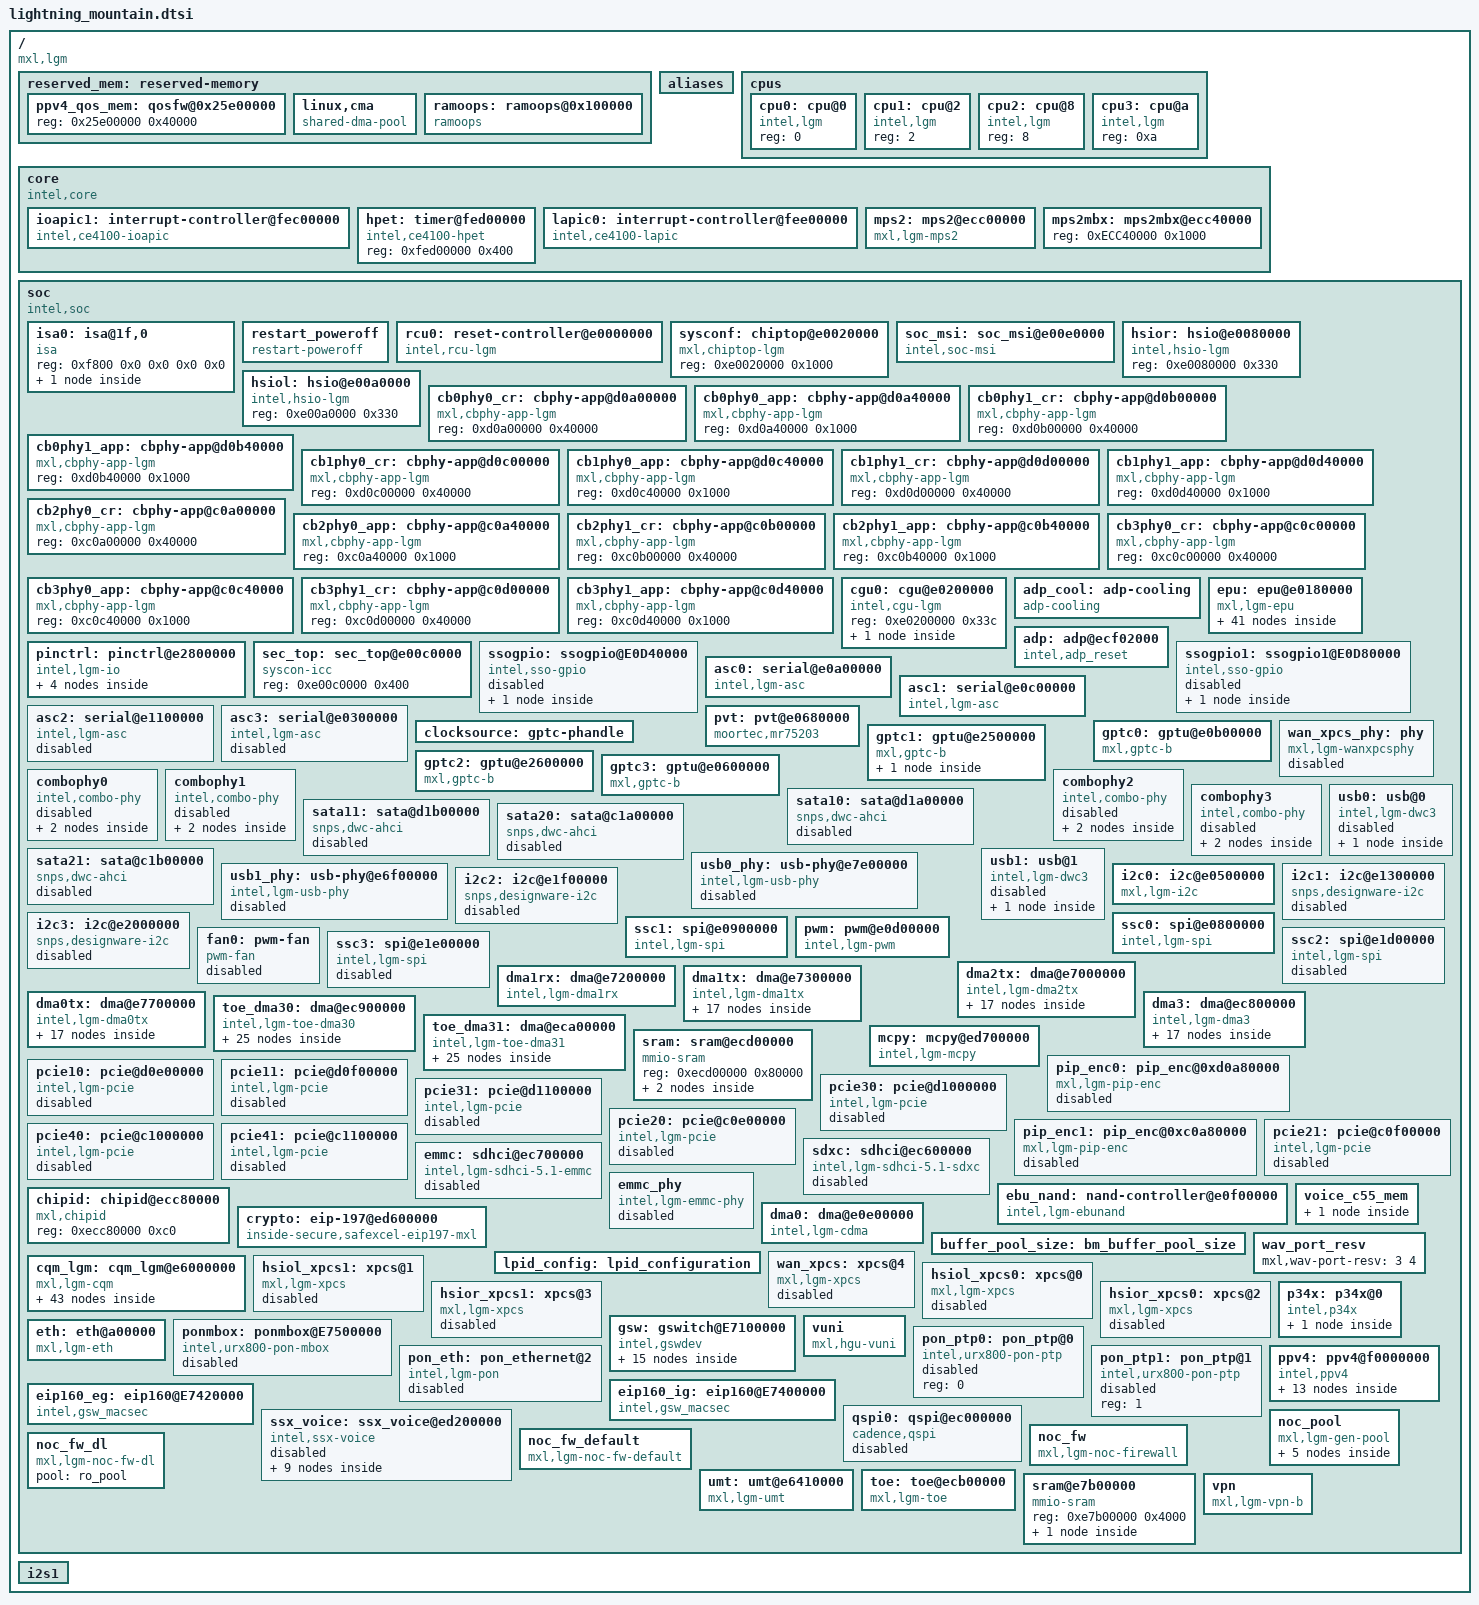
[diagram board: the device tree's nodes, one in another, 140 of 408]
// SPDX-License-Identifier: GPL-2.0
/*
 * Copyright (C) 2020-2024 MaxLinear, Inc.
 * Copyright (C) 2018-2020 Intel Corporation.
 */

#include <dt-bindings/clock/intel,lgm-clk.h>
#include <dt-bindings/phy/intel,phy-combo.h>
#include <dt-bindings/soc/mxl,firewall.h>
#include <dt-bindings/power/lgm-power.h>
#include <dt-bindings/net/mxl,lgm-cqm.h>
#include <dt-bindings/net/mxl,gswss.h>
#include <dt-bindings/net/mxl,vuni.h>

/ {
	#address-cells = <1>;
	#size-cells = <1>;
	compatible = "mxl,lgm", "intel,lgm";

	reserved_mem: reserved-memory {
		#address-cells = <1>;
		#size-cells = <1>;
		ranges;

		ppv4_qos_mem: qosfw@0x25e00000 {
			reg = <0x25e00000 0x40000>;
		};

		linux,cma {
			compatible = "shared-dma-pool";
			reusable;
			alignment = <0x200000>;
			size = <0x3f000000>;
			linux,cma-default;
		};

		ramoops: ramoops@0x100000 {
			compatible = "ramoops";
			reg = <0x100000 0x10000>;
			record-size = <0x10000>;
		};
	};

	aliases {
		serial0 = &asc0;
		serial1 = &asc1;
		serial2 = &asc2;
		serial3 = &asc3;
		dma0    = &dma2tx;
		dma1    = &dma1rx;
		dma2    = &dma1tx;
		dma3    = &dma0tx;
		dma4    = &dma3;
		dma5    = &toe_dma30;
		dma6    = &toe_dma31;
		pcie0   = &pcie10;
		pcie1   = &pcie11;
		pcie2   = &pcie30;
		pcie3   = &pcie31;
		pcie4   = &pcie20;
		pcie5   = &pcie21;
		pcie6   = &pcie40;
		pcie7   = &pcie41;
		timer0  = &gptc0;
		timer1  = &gptc1;
		timer2  = &gptc2;
		timer3  = &gptc3;
		cpu0    = &cpu0;
		cpu1    = &cpu1;
		cpu2    = &cpu2;
		cpu3    = &cpu3;
		isa0	= &isa0;
		usb0    = &usb0;
		usb1	= &usb1;
		mmc0	= &emmc;
		mmc1	= &sdxc;
		cbphy0  = &combophy0;
		cbphy1  = &combophy1;
		cbphy2  = &combophy2;
		cbphy3  = &combophy3;
		vcodec0 = &vcodec0;
		vcodec1 = &vcodec1;
		socpool = &noc_pool;
	};

	cpus {
		#address-cells = <1>;
		#size-cells = <0>;
		cpu0:cpu@0 {
			device_type = "cpu";
			compatible = "intel,lgm";
			reg = <0>;
			#cooling-cells = <2>; /* min followed by max */
		};

		cpu1:cpu@2 {
			device_type = "cpu";
			compatible = "intel,lgm";
			reg = <2>;
			#cooling-cells = <2>; /* min followed by max */
		};

		cpu2:cpu@8 {
			device_type = "cpu";
			compatible = "intel,lgm";
			reg = <8>;
			#cooling-cells = <2>; /* min followed by max */
		};

		cpu3:cpu@a {
			device_type = "cpu";
			compatible = "intel,lgm";
			reg = <0xa>;
			#cooling-cells = <2>; /* min followed by max */
		};
	};

	/* Special part from CPU core */
	core: core {
		compatible = "intel,core", "simple-bus";
		#address-cells = <1>;
		#size-cells = <1>;
		ranges;

		ioapic1: interrupt-controller@fec00000 {
			#interrupt-cells = <2>;
			#address-cells = <0>;
			compatible = "intel,ce4100-ioapic";
			interrupt-controller;
			reg = <0xfec00000 0x1000>;
			nr_entries = <256>;
		};

		hpet: timer@fed00000 {
			compatible = "intel,ce4100-hpet";
			reg = <0xfed00000 0x400>;
		};

		lapic0: interrupt-controller@fee00000 {
			compatible = "intel,ce4100-lapic";
			reg = <0xfee00000 0x1000>;
			no_pic_mode;
		};

		mps2: mps2@ecc00000 {
			status = "okay";
			compatible = "mxl,lgm-mps2", "syscon-icc", "syscon";
			reg = <0xECC00000 0x33F>;
			interrupt-parent = <&ioapic1>;
			interrupts = <168 1>;
			mxl,mbx = <&mps2mbx>;
		};

		mps2mbx: mps2mbx@ecc40000 {
			reg = <0xECC40000 0x1000>;
		};
	};

	/* Flat cross bar */
	soc: soc {
		compatible = "intel,soc", "simple-bus";
		#address-cells = <1>;
		#size-cells = <1>;
		ranges;

                isa0: isa@1f,0 {
			#address-cells = <2>;
			#size-cells = <1>;
			compatible = "isa";
			reg = <0xf800 0x0 0x0 0x0 0x0>;
			ranges = <1 0 0 0 0 0x100>;

			rtc@70 {
				compatible = "intel,ce4100-rtc", "motorola,mc146818";
				interrupts = <8 3>;
				interrupt-parent = <&ioapic1>;
				ctrl-reg = <2>;
				freq-reg = <0x26>;
				reg = <1 0x70 2>;
				status = "disabled";
			};
		};

		restart_poweroff {
			compatible = "restart-poweroff";
		};

		rcu0: reset-controller@e0000000 {
			compatible = "intel,rcu-lgm", "syscon-icc", "syscon";
			reg = <0xe0000000 0x20000>;
			#reset-cells = <2>;
			intel,global-reset = <0x10 30>;
		};

		sysconf: chiptop@e0020000 {
			compatible = "mxl,chiptop-lgm", "syscon-icc", "syscon";
			reg = <0xe0020000 0x1000>;
			#reset-cells = <1>;
		};

		soc_msi: soc_msi@e00e0000 {
			compatible = "intel,soc-msi";
			reg = <0xe00e0000 0x800>;
			interrupt-controller;
			#interrupt-cells = <1>;
			dma-coherent;
		};

		hsior:hsio@e0080000 {
			compatible = "intel,hsio-lgm", "syscon";
			reg = <0xe0080000 0x330>;
		};

		hsiol:hsio@e00a0000 {
			compatible = "intel,hsio-lgm", "syscon";
			reg = <0xe00a0000 0x330>;
		};

		cb0phy0_cr: cbphy-app@d0a00000 {
			compatible = "mxl,cbphy-app-lgm", "syscon";
			reg = <0xd0a00000 0x40000>;
		};

		cb0phy0_app: cbphy-app@d0a40000 {
			compatible = "mxl,cbphy-app-lgm", "syscon";
			reg = <0xd0a40000 0x1000>;
		};

		cb0phy1_cr: cbphy-app@d0b00000 {
			compatible = "mxl,cbphy-app-lgm", "syscon";
			reg = <0xd0b00000 0x40000>;
		};

		cb0phy1_app: cbphy-app@d0b40000 {
			compatible = "mxl,cbphy-app-lgm", "syscon";
			reg = <0xd0b40000 0x1000>;
		};

		cb1phy0_cr: cbphy-app@d0c00000 {
			compatible = "mxl,cbphy-app-lgm", "syscon";
			reg = <0xd0c00000 0x40000>;
		};

		cb1phy0_app: cbphy-app@d0c40000 {
			compatible = "mxl,cbphy-app-lgm", "syscon";
			reg = <0xd0c40000 0x1000>;
		};

		cb1phy1_cr: cbphy-app@d0d00000 {
			compatible = "mxl,cbphy-app-lgm", "syscon";
			reg = <0xd0d00000 0x40000>;
		};

		cb1phy1_app: cbphy-app@d0d40000 {
			compatible = "mxl,cbphy-app-lgm", "syscon";
			reg = <0xd0d40000 0x1000>;
		};

		cb2phy0_cr: cbphy-app@c0a00000 {
			compatible = "mxl,cbphy-app-lgm", "syscon";
			reg = <0xc0a00000 0x40000>;
		};

		cb2phy0_app: cbphy-app@c0a40000 {
			compatible = "mxl,cbphy-app-lgm", "syscon";
			reg = <0xc0a40000 0x1000>;
		};

		cb2phy1_cr: cbphy-app@c0b00000 {
			compatible = "mxl,cbphy-app-lgm", "syscon";
			reg = <0xc0b00000 0x40000>;
		};

		cb2phy1_app: cbphy-app@c0b40000 {
			compatible = "mxl,cbphy-app-lgm", "syscon";
			reg = <0xc0b40000 0x1000>;
		};

		cb3phy0_cr: cbphy-app@c0c00000 {
			compatible = "mxl,cbphy-app-lgm", "syscon";
			reg = <0xc0c00000 0x40000>;
		};

		cb3phy0_app: cbphy-app@c0c40000 {
			compatible = "mxl,cbphy-app-lgm", "syscon";
			reg = <0xc0c40000 0x1000>;
		};

		cb3phy1_cr: cbphy-app@c0d00000 {
			compatible = "mxl,cbphy-app-lgm", "syscon";
			reg = <0xc0d00000 0x40000>;
		};

		cb3phy1_app: cbphy-app@c0d40000 {
			compatible = "mxl,cbphy-app-lgm", "syscon";
			reg = <0xc0d40000 0x1000>;
		};

		cgu0: cgu@e0200000 {
			#address-cells = <1>;
			#size-cells = <1>;
			compatible = "intel,cgu-lgm", "syscon-icc", "syscon";
			reg = <0xe0200000 0x33c>;
			#clock-cells = <1>;

			afeclk: afeclk {
				#clock-cells = <0>;
				compatible = "fixed-clock";
				clock-frequency = <8000>;
				clock-output-names = "afeclk";
			};
		};

		adp_cool: adp-cooling {
			compatible = "adp-cooling";
			#cooling-cells = <2>;
		};

		epu: epu@e0180000 {
			compatible = "mxl,lgm-epu", "syscon-icc", "syscon";
			reg = <0xe0180000 0x2000    /* EPU_AON */
			       0xe0100000 0x26000>; /* EPU_GEN */
			reg-names = "epu_aon", "epu_gen";
			mxl,top-syscon = <&sysconf>;
			clocks = <&cgu0 LGM_CLK_OSC>;
			interrupt-parent = <&ioapic1>;
			interrupts = <99 1>,
				     <100 1>;
			interrupt-names = "epu_irq0", "epu_irq1";

			/*
			 * Note: LGM supports up to voltage domains including
			 * V080_CPU_MO, V080_CPU_M1, V080_ADP, V080_RoC and
			 * V080_AON
			 */

			#address-cells = <1>;
			#size-cells = <0>;

			/* ADP */
			pd_ppv4: pd_ppv4@LGM_EPU_PD_PPV4 {
				reg = <LGM_EPU_PD_PPV4>;
				#power-domain-cells = <0>;
			};

			pd_gsw: pd_gsw@LGM_EPU_PD_GSW {
				reg = <LGM_EPU_PD_GSW>;
				#power-domain-cells = <0>;
			};

			pd_cqm: pd_cqm@LGM_EPU_PD_CQM {
				reg = <LGM_EPU_PD_CQM>;
				#power-domain-cells = <0>;
			};

			pd_eip197: pd_eip197@LGM_EPU_PD_EIP197 {
				reg = <LGM_EPU_PD_EIP197>;
				#power-domain-cells = <0>;
			};

			pd_toe: pd_toe@LGM_EPU_PD_TOE {
				reg = <LGM_EPU_PD_TOE>;
				#power-domain-cells = <0>;
			};

			/* RoC */
			pd_hsio1: pd_hsio1@LGM_EPU_PD_HSIO1 {
				reg = <LGM_EPU_PD_HSIO1>;
				#power-domain-cells = <0>;
			};

			pd_hsio2: pd_hsio2@LGM_EPU_PD_HSIO2 {
				reg = <LGM_EPU_PD_HSIO2>;
				#power-domain-cells = <0>;
			};

			pd_hsio3: pd_hsio3@LGM_EPU_PD_HSIO3 {
				reg = <LGM_EPU_PD_HSIO3>;
				#power-domain-cells = <0>;
			};

			pd_hsio4: pd_hsio4@LGM_EPU_PD_HSIO4 {
				reg = <LGM_EPU_PD_HSIO4>;
				#power-domain-cells = <0>;
			};

			pd_sdxc: pd_sdxc@LGM_EPU_PD_SDXC {
				reg = <LGM_EPU_PD_SDXC>;
				#power-domain-cells = <0>;
			};

			pd_emmc: pd_emmc@LGM_EPU_PD_EMMC {
				reg = <LGM_EPU_PD_EMMC>;
				#power-domain-cells = <0>;
			};

			pd_qspi: pd_qspi@LGM_EPU_PD_QSPI {
				reg = <LGM_EPU_PD_QSPI>;
				#power-domain-cells = <0>;
			};

			pd_asc0: pd_asc0@LGM_EPU_PD_ASC0 {
				reg = <LGM_EPU_PD_ASC0>;
				#power-domain-cells = <0>;
			};

			pd_asc2: pd_asc2@LGM_EPU_PD_ASC2 {
				reg = <LGM_EPU_PD_ASC2>;
				#power-domain-cells = <0>;
			};

			pd_ssc0: pd_ssc0@LGM_EPU_PD_SSC0 {
				reg = <LGM_EPU_PD_SSC0>;
				#power-domain-cells = <0>;
			};

			pd_ssc1: pd_ssc1@LGM_EPU_PD_SSC1 {
				reg = <LGM_EPU_PD_SSC1>;
				#power-domain-cells = <0>;
			};

			pd_ssc2: pd_ssc2@LGM_EPU_PD_SSC2 {
				reg = <LGM_EPU_PD_SSC2>;
				#power-domain-cells = <0>;
			};

			pd_ssc3: pd_ssc3@LGM_EPU_PD_SSC3 {
				reg = <LGM_EPU_PD_SSC3>;
				#power-domain-cells = <0>;
			};

			pd_i2c1: pd_i2c1@LGM_EPU_PD_I2C1 {
				reg = <LGM_EPU_PD_I2C1>;
				#power-domain-cells = <0>;
			};

			pd_i2c2: pd_i2c2@LGM_EPU_PD_I2C2 {
				reg = <LGM_EPU_PD_I2C2>;
				#power-domain-cells = <0>;
			};

			pd_i2c3: pd_i2c3@LGM_EPU_PD_I2C3 {
				reg = <LGM_EPU_PD_I2C3>;
				#power-domain-cells = <0>;
			};

			pd_ebu: pd_ebu@LGM_EPU_PD_EBU {
				reg = <LGM_EPU_PD_EBU>;
				#power-domain-cells = <0>;
			};

			pd_i2s0: pd_i2s0@LGM_EPU_PD_I2S0 {
				reg = <LGM_EPU_PD_I2S0>;
				#power-domain-cells = <0>;
			};

			pd_i2s1: pd_i2s1@LGM_EPU_PD_I2S1 {
				reg = <LGM_EPU_PD_I2S1>;
				#power-domain-cells = <0>;
			};

			pd_ledc0: pd_ledc0@LGM_EPU_PD_LEDC0 {
				reg = <LGM_EPU_PD_LEDC0>;
				#power-domain-cells = <0>;
			};

			pd_ledc1: pd_ledc1@LGM_EPU_PD_LEDC1 {
				reg = <LGM_EPU_PD_LEDC1>;
				#power-domain-cells = <0>;
			};

			pd_usb1: pd_usb1@LGM_EPU_PD_USB1 {
				reg = <LGM_EPU_PD_USB1>;
				#power-domain-cells = <0>;
			};

			pd_usb2: pd_usb2@LGM_EPU_PD_USB2 {
				reg = <LGM_EPU_PD_USB2>;
				#power-domain-cells = <0>;
			};

			pd_sata0: pd_sata0@LGM_EPU_PD_SATA0 {
				reg = <LGM_EPU_PD_SATA0>;
				#power-domain-cells = <0>;
				status = "disabled";
			};

			pd_sata1: pd_sata1@LGM_EPU_PD_SATA1 {
				reg = <LGM_EPU_PD_SATA1>;
				#power-domain-cells = <0>;
				status = "disabled";
			};

			pd_sata2: pd_sata2@LGM_EPU_PD_SATA2 {
				reg = <LGM_EPU_PD_SATA2>;
				#power-domain-cells = <0>;
				status = "disabled";
			};

			pd_sata3: pd_sata3@LGM_EPU_PD_SATA3 {
				reg = <LGM_EPU_PD_SATA3>;
				#power-domain-cells = <0>;
				status = "disabled";
			};

			pd_pcie10: pd_pcie10@LGM_EPU_PD_PCIE10 {
		
				reg = <LGM_EPU_PD_PCIE10>;
				#power-domain-cells = <0>;
				status = "disabled";
			};

			pd_pcie11: pd_pcie11@LGM_EPU_PD_PCIE11 {
		
				reg = <LGM_EPU_PD_PCIE11>;
				#power-domain-cells = <0>;
				status = "disabled";
			};

			pd_pcie20: pd_pcie20@LGM_EPU_PD_PCIE20 {
				reg = <LGM_EPU_PD_PCIE20>;
				#power-domain-cells = <0>;
				status = "disabled";
			};

			pd_pcie21: pd_pcie21@LGM_EPU_PD_PCIE21 {
				reg = <LGM_EPU_PD_PCIE21>;
				#power-domain-cells = <0>;
				status = "disabled";
			};
/*
			pd_pcie30: pd_pcie30@LGM_EPU_PD_PCIE30 {
				reg = <LGM_EPU_PD_PCIE30>;
				#power-domain-cells = <0>;
			};

			pd_pcie31: pd_pcie31@LGM_EPU_PD_PCIE31 {
				reg = <LGM_EPU_PD_PCIE31>;
				#power-domain-cells = <0>;
			};
*/
			pd_pcie40: pd_pcie40@LGM_EPU_PD_PCIE40 {
				reg = <LGM_EPU_PD_PCIE40>;
				#power-domain-cells = <0>;
				status = "disabled";
			};

			pd_pcie41: pd_pcie41@LGM_EPU_PD_PCIE41 {
				reg = <LGM_EPU_PD_PCIE41>;
				#power-domain-cells = <0>;
				status = "disabled";
			};
/*
			pd_xpcs10: pd_xpcs10@LGM_EPU_PD_XPCS10 {
				reg = <LGM_EPU_PD_XPCS10>;
				#power-domain-cells = <0>;
			};
*/
			pd_xpcs11: pd_xpcs11@LGM_EPU_PD_XPCS11 {
				reg = <LGM_EPU_PD_XPCS11>;
				#power-domain-cells = <0>;
				status = "disabled";
			};
/*
			pd_xpcs20: pd_xpcs20@LGM_EPU_PD_XPCS20 {
				reg = <LGM_EPU_PD_XPCS20>;
				#power-domain-cells = <0>;
			};
*/
			pd_xpcs21: pd_xpcs21@LGM_EPU_PD_XPCS21 {
				reg = <LGM_EPU_PD_XPCS21>;
				#power-domain-cells = <0>;
				status = "disabled";
			};

			pd_voice: pd_voice@LGM_EPU_PD_VOICE {
				reg = <LGM_EPU_PD_VOICE>;
				#power-domain-cells = <0>;
			};
		};

		pinctrl: pinctrl@e2800000 {
			compatible = "intel,lgm-io";
			reg = <0xe2880000 0x100000>;
			#address-cells = <1>;
			#size-cells = <1>;
			#pinctrl-cells = <2>;
			ranges;

			pinctrl,syscon = <&sysconf>;
			gpio0: gpio@e2800000 {
				gpio-controller;
				#gpio-cells = <2>;
				reg = <0xe2800000 0x80>;
				interrupt-controller;
				#interrupt-cells = <2>;
				interrupt-parent = <&ioapic1>;
				interrupts = <135 1>;
				gpio-ranges = <&pinctrl 0 0 32>;
			};

			gpio1: gpio@e2800100 {
				gpio-controller;
				#gpio-cells = <2>;
				reg = <0xe2800100 0x80>;
				interrupt-controller;
				#interrupt-cells = <2>;
				interrupt-parent = <&ioapic1>;
				interrupts = <136 1>;
				gpio-ranges = <&pinctrl 0 32 32>;
			};

			gpio2: gpio@e2800200 {
				gpio-controller;
				#gpio-cells = <2>;
				reg = <0xe2800200 0x80>;
				interrupt-controller;
				#interrupt-cells = <2>;
				interrupt-parent = <&ioapic1>;
				interrupts = <137 1>;
				gpio-ranges = <&pinctrl 0 64 32>;
			};

			gpio3: gpio@e2800300 {
				gpio-controller;
				#gpio-cells = <2>;
				reg = <0xe2800300 0x80>;
				interrupt-controller;
				#interrupt-cells = <2>;
				interrupt-parent = <&ioapic1>;
				interrupts = <138 1>;
				gpio-ranges = <&pinctrl 0 96 8>;
			};
		};

		sec_top: sec_top@e00c0000 {
			compatible = "syscon-icc", "syscon";
			reg = <0xe00c0000 0x400>;
		};

		adp: adp@ecf02000 {
			compatible = "intel,adp_reset", "syscon-icc", "syscon";
			reg = <0xecf02000 0x1000
			       0xed500000 0x20000
			       0xe7f00000 0x8000>;
			reg-names = "eth_fw", "top_noc", "eth_noc";
			intel,sec-syscon = <&sec_top>;
			intel,top-syscon = <&sysconf>;
			intel,rcu-syscon = <&rcu0>;
			intel,epu-syscon = <&epu>;
			intel,cgu-syscon = <&cgu0>;
		};

		ssogpio: ssogpio@E0D40000 {
			status = "disabled";
			compatible = "intel,sso-gpio", "syscon", "simple-mfd";
			gpio-controller;
			#gpio-cells = <2>;
			reg = <0xE0D40000 0x2E4>;
			ngpios = <32>;
			pinctrl-names = "default";
			pinctrl-0 = <&pinctrl_ledc0>;
			clocks = <&cgu0 LGM_GCLK_LEDC0>;
			clock-names = "sso";
			resets = <&rcu0 0x30 22>;
			power-domains = <&pd_ledc0>;

			ssoled:ssoled {
				status = "disabled";
				compatible = "mxl,sso-led";
				mxl,fpid-clkrate= <8000>;
				mxl,gptc-clkrate = <200000000>;
				mxl,sso-def-updatesrc = <1>;
			};
		};

		ssogpio1: ssogpio1@E0D80000 {
			status = "disabled";
			compatible = "intel,sso-gpio", "syscon", "simple-mfd";
			gpio-controller;
			#gpio-cells = <2>;
			reg = <0xE0D80000 0x2E4>;
			ngpios = <32>;
			pinctrl-names = "default";
			pinctrl-0 = <&pinctrl_ledc1>;
			clocks = <&cgu0 LGM_GCLK_LEDC1>;
			clock-names = "sso";
			resets = <&rcu0 0x30 23>;
			power-domains = <&pd_ledc1>;

			ssoled1:ssoled1 {
				status = "disabled";
				compatible = "mxl,sso-led";
				mxl,fpid-clkrate= <8000>;
				mxl,gptc-clkrate = <200000000>;
				mxl,sso-def-updatesrc = <1>;
			};
		};

		asc0: serial@e0a00000 {
			compatible = "intel,lgm-asc";
			reg = <0xe0a00000 0x1000>;
			interrupt-parent = <&ioapic1>;
			interrupts = <128 1>;
			interrupt-names = "asc_irq";
			clocks = <&cgu0 LGM_CLK_NOC4>, <&cgu0 LGM_GCLK_ASC0>;
			clock-names = "freq", "asc";
			pinctrl-names = "default";
			pinctrl-0 = <&uart0>;
			power-domains = <&pd_asc0>;
		};

		asc1: serial@e0c00000 {
			compatible = "intel,lgm-asc";
			reg = <0xe0c00000 0x1000>;
			interrupt-parent = <&ioapic1>;
			interrupts = <111 1>;
			interrupt-names = "asc_irq";
			clocks = <&cgu0 LGM_CLK_NOC4>, <&cgu0 LGM_GCLK_ASC1>;
			clock-names = "freq", "asc";
			pinctrl-names = "default";
			pinctrl-0 = <&uart1>;
		};

		asc2: serial@e1100000 {
			status = "disabled";
			compatible = "intel,lgm-asc";
			reg = <0xe1100000 0x1000>;
			interrupt-parent = <&ioapic1>;
			interrupts = <129 1>;
			interrupt-names = "asc_irq";
			clocks = <&cgu0 LGM_CLK_NOC4>, <&cgu0 LGM_GCLK_ASC2>;
			clock-names = "freq", "asc";
			pinctrl-names = "default";
			pinctrl-0 = <&uart2>;
			power-domains = <&pd_asc2>;
		};

		asc3: serial@e0300000 {
			status = "disabled";
			compatible = "intel,lgm-asc";
			reg = <0xe0300000 0x1000>;
			interrupt-parent = <&ioapic1>;
			interrupts = <130 1>;
			interrupt-names = "asc_irq";
			clocks = <&cgu0 LGM_CLK_NOC4>, <&cgu0 LGM_GCLK_ASC3>;
			clock-names = "freq", "asc";
			pinctrl-names = "default";
			pinctrl-0 = <&uart3>;
		};

		pvt: pvt@e0680000 {
			compatible = "moortec,mr75203";
			reg = <0xe0680000 0x80
				0xe0680080 0x180
				0xe0680200 0x200
				0xe0680400 0xc00>;
			reg-names = "common", "ts", "pd", "vm";
			interrupt-parent = <&ioapic1>;
			interrupts = <26 1>;
			intel,vm-map = [01 03 04 ff ff];
			moortec,vm-active-channels = /bits/ 8 <0x01 0x01 0x01 0x00 0x00>;
			clocks = <&cgu0 LGM_CLK_OSC>;
			resets = <&rcu0 0x40 7>;
			#thermal-sensor-cells = <1>;
		};

		clocksource: gptc-phandle {
			#gptc-cells = <5>;
		};

		gptc0: gptu@e0b00000 {
			compatible = "mxl,gptc-b", "syscon", "simple-mfd";
			reg = <0xe0b00000 0x10000>;
			interrupts-extended = <&ioapic1 188 1>, <&ioapic1 189 1>,
				<&soc_msi 63>, <&soc_msi 62>;
			interrupt-names = "tc1a", "tc1b", "tc2a", "tc3a";
			mxl,clk = <&clocksource 2 0 0 32 0>, /* Heartbeat timer 1 */
				<&clocksource 3 1 0 32 0>, /* SSO timer 2 */
				<&clocksource 0 2 1 32 0>; /* Prewarn timer 3 */
			prewarn-num = <1>;
			prewarn-timer = <2 1 3>;
			mxl,wdt-rst-base = <&sysconf>;
			clocks = <&cgu0 LGM_CLK_NOC4>, <&cgu0 LGM_GCLK_GPTC0>;
			clock-names = "freq", "gptc";
		};

		gptc1: gptu@e2500000 {
			compatible = "mxl,gptc-b", "syscon", "simple-mfd";
			reg = <0xe2500000 0x10000>;
			interrupt-parent = <&soc_msi>;
			interrupts = <49>;
			interrupt-names = "tc1a";
			mxl,clk = <&clocksource 0 0 2 32 0>, /* Prewarn timer 1 */
				<&clocksource 1 1 0 32 0>,  /* Watchdog timer 2 */
				<&clocksource 1 2 1 32 0>; /* Watchdog timer 3 */
			prewarn-num = <0>;
			prewarn-timer = <0 2 0>;
			wdt-num = <1>;
			wdt-timer = <2 1>;
			mxl,wdt-rst-base = <&sysconf>;
			clocks = <&cgu0 LGM_CLK_NOC4>, <&cgu0 LGM_GCLK_GPTC1>;
			clock-names = "freq", "gptc";

			wdt0: watchdog {
				compatible = "mxl,gptc-wdt";
				timeout-sec = <30>;
				mxl,wdt-rst-base = <&sysconf>;
			};
		};

		gptc2: gptu@e2600000 {
			compatible = "mxl,gptc-b", "syscon", "simple-mfd";
			reg = <0xe2600000 0x10000>;
			interrupt-parent = <&soc_msi>;
			interrupts = <47>;
			interrupt-names = "tc1a";
			mxl,clk = <&clocksource 0 0 3 32 0>, /* Prewarn timer 1 */
				<&clocksource 1 1 2 32 0>, /* Watchdog timer 2 */
				<&clocksource 1 2 3 32 0>;  /* Watchdog timer 3 */
			prewarn-num = <0>;
			prewarn-timer = <0 3 0>;
			wdt-num = <0>;
			wdt-timer = <1 2>, <2 3>;
			mxl,wdt-rst-base = <&sysconf>;
			clocks = <&cgu0 LGM_CLK_NOC4>, <&cgu0 LGM_GCLK_GPTC2>;
			clock-names = "freq", "gptc";
		};

		gptc3: gptu@e0600000 {
			compatible = "mxl,gptc-b", "syscon", "simple-mfd";
			reg = <0xe0600000 0x10000>;
			interrupt-parent = <&ioapic1>;
			interrupts = <183 1>,
				<181 1>,
				<182 1>;
			interrupt-names = "tc1a", "tc2a", "tc3a";
			mxl,clk = <&clocksource 2 0 0 32 0>; /* Heartbeat timer 1 */
			mxl,wdt-rst-base = <&sysconf>;
			clocks = <&cgu0 LGM_CLK_OSC>, <&cgu0 LGM_GCLK_GPTC3>;
			clock-names = "freq", "gptc";
		};

		wan_xpcs_phy: phy {
			status = "disabled";
			compatible = "mxl,lgm-wanxpcsphy";
			reg = <0xe7840000 0x1000
			       0xe7800000 0x10000
			       0xe7843000 0x1000>;
			reg-names = "pon_shell", "cr", "app";
			#phy-cells = <0>;
			resets = <&rcu0 0x70 9>;
			reset-names = "pon";
			clocks = <&cgu0 LGM_CLK_SERDES>;
		};

		combophy0:combophy0 {
			status = "disabled";
			compatible = "intel,combo-phy", "simple-bus";
			#address-cells = <1>;
			#size-cells = <1>;
			ranges;

			resets = <&rcu0 0x50 17>, /* Combo */
				 <&rcu0 0x50 6>;  /* PCIe 10/11 PHY */
			reset-names = "combo", "phy";
			clocks = <&cgu0 LGM_CLK_CBPHY0>;
			intel,syscon = <&sysconf>; /* chiptop */
			intel,hsio = <&hsiol>; /* hsiol cbphy0 */
			intel,bid = <0>; /* hsio bus id */
			intel,epu-idx = <1>;
			power-domains = <&pd_hsio1>;

			cb0phy0:cb0phy@0 { /* PCIe 10/XPCS 0/SATA 0 */
				compatible = "intel,cbphy";
				#phy-cells = <1>;
				mxl,cr = <&cb0phy0_cr>;
				mxl,app = <&cb0phy0_app>;
				resets = <&rcu0 0x50 23>,
					 <&rcu0 0x50 12>;
				reset-names = "pcie", "xpcs";
			};

			cb0phy1:cb0phy@1 { /* PCIe 11/XPCS 1/SATA 1 */
				compatible = "intel,cbphy";
				#phy-cells = <1>;
				mxl,cr = <&cb0phy1_cr>;
				mxl,app = <&cb0phy1_app>;
				resets = <&rcu0 0x50 24>,
					 <&rcu0 0x50 13>;
				reset-names = "pcie", "xpcs";
			};
		};

		combophy1:combophy1 {
			status = "disabled";
			compatible = "intel,combo-phy", "simple-bus";
			#address-cells = <1>;
			#size-cells = <1>;
			ranges;

			resets = <&rcu0 0x50 8>, /* PCIe 30/31 PHY */
				 <&rcu0 0x50 18>;/* Combo */
			reset-names = "phy", "combo";
			clocks = <&cgu0 LGM_CLK_CBPHY1>;
			intel,syscon = <&sysconf>; /* chiptop */
			intel,hsio = <&hsiol>; /* hsiol cbphy1 */
			intel,bid = <1>; /* hsio bus id */
			intel,cbphy-pcie;
			power-domains = <&pd_hsio3>;

			cb1phy0:cb1phy@0 { /* PCIe 30 */
				compatible = "intel,cbphy";
				#phy-cells = <1>;
				mxl,cr = <&cb1phy0_cr>;
				mxl,app = <&cb1phy0_app>;
				resets = <&rcu0 0x50 25>;
				reset-names = "pcie"; /* pe */
			};

			cb1phy1:cb1phy@1 { /* PCIe 31 */
				compatible = "intel,cbphy";
				#phy-cells = <1>;
				mxl,cr = <&cb1phy1_cr>;
				mxl,app = <&cb1phy1_app>;
				resets = <&rcu0 0x50 26>;
				reset-names = "pcie"; /* pe */
			};
		};

		combophy2:combophy2 {
			status = "disabled";
			compatible = "intel,combo-phy", "simple-bus";
			#address-cells = <1>;
			#size-cells = <1>;
			ranges;

			resets = <&rcu0 0x60 17>, /* COMBO */
				 <&rcu0 0x60 6>;  /* PCIe 20/21 PHY */
			reset-names = "combo", "phy";
			clocks = <&cgu0 LGM_CLK_CBPHY2>;
			intel,syscon = <&sysconf>; /* chiptop */
			intel,hsio = <&hsior>; /* hsior cbphy0 */
			intel,bid = <0>; /* hsio bus id */
			intel,epu-idx = <2>;
			power-domains = <&pd_hsio2>;

			cb2phy0:cb2phy@0 { /* PCIe 20/XPCS 2/SATA 2 */
				compatible = "intel,cbphy";
				#phy-cells = <1>;
				mxl,cr = <&cb2phy0_cr>;
				mxl,app = <&cb2phy0_app>;
				resets = <&rcu0 0x60 23>,
					 <&rcu0 0x60 12>;
				reset-names = "pcie", "xpcs";
			};

			cb2phy1:cb2phy@1 { /* PCIe 21/XPCS 3/SATA 3 */
				compatible = "intel,cbphy";
				#phy-cells = <1>;
				mxl,cr = <&cb2phy1_cr>;
				mxl,app = <&cb2phy1_app>;
				resets = <&rcu0 0x60 24>,
					 <&rcu0 0x60 13>;
				reset-names = "pcie", "xpcs";
			};
		};

		combophy3:combophy3 {
			status = "disabled";
			compatible = "intel,combo-phy", "simple-bus";
			#address-cells = <1>;
			#size-cells = <1>;
			ranges;

			resets = <&rcu0 0x60 8>, /* PCIe 40/41 PHY */
				 <&rcu0 0x60 18>;/* Combo */
			reset-names = "phy", "combo";
			clocks = <&cgu0 LGM_CLK_CBPHY3>;
			intel,syscon = <&sysconf>; /* chiptop */
			intel,hsio = <&hsior>; /* hsior cbphy1 */
			intel,bid = <1>; /* hsio bus id */
			intel,cbphy-pcie;
			power-domains = <&pd_hsio4>;

			cb3phy0:cb3phy@0 { /* PCIe 40 */
				compatible = "intel,cbphy";
				#phy-cells = <1>;
				mxl,cr = <&cb3phy0_cr>;
				mxl,app = <&cb3phy0_app>;
				resets = <&rcu0 0x60 25>;
				reset-names = "pcie"; /* pe */
			};

			cb3phy1:cb3phy@1 { /* PCIe 41 */
				compatible = "intel,cbphy";
				#phy-cells = <1>;
				mxl,cr = <&cb3phy1_cr>;
				mxl,app = <&cb3phy1_app>;
				resets = <&rcu0 0x60 26>;
				reset-names = "pcie";  /* pe */
			};
		};

		sata10: sata@d1a00000 {
			status = "disabled";
			compatible = "snps,dwc-ahci";
			reg = <0xd1a00000 0x200>;
			interrupt-parent = <&soc_msi>;
			interrupts = <46>;
			clocks = <&cgu0 LGM_GCLK_SATA0>;
			resets = <&rcu0 0x50 15>;
			phys = <&cb0phy0 PHY_TYPE_SATA_SL>;
			phy-names = "sata-phy";
			ports-implemented = <0x1>;
			dma-coherent;
		};

		sata11: sata@d1b00000 {
			status = "disabled";
			compatible = "snps,dwc-ahci";
			reg = <0xd1b00000 0x200>;
			interrupt-parent = <&ioapic1>;
			interrupts = <87 1>;
			clocks = <&cgu0 LGM_GCLK_SATA1>;
			resets = <&rcu0 0x50 16>;
			phys = <&cb0phy1 PHY_TYPE_SATA_SL>;
			phy-names = "sata-phy";
			ports-implemented = <0x1>;
			dma-coherent;
		};

		sata20: sata@c1a00000 {
			status = "disabled";
			compatible = "snps,dwc-ahci";
			reg = <0xc1a00000 0x200>;
			interrupt-parent = <&soc_msi>;
			interrupts = <48>;
			clocks = <&cgu0 LGM_GCLK_SATA2>;
			resets = <&rcu0 0x60 15>;
			phys = <&cb2phy0 PHY_TYPE_SATA_SL>;
			phy-names = "sata-phy";
			ports-implemented = <0x1>;
			dma-coherent;
		};

		sata21: sata@c1b00000 {
			status = "disabled";
			compatible = "snps,dwc-ahci";
			reg = <0xc1b00000 0x200>;
			interrupt-parent = <&ioapic1>;
			interrupts = <93 1>;
			clocks = <&cgu0 LGM_GCLK_SATA3>;
			resets = <&rcu0 0x60 16>;
			phys = <&cb2phy1 PHY_TYPE_SATA_SL>;
			phy-names = "sata-phy";
			ports-implemented = <0x1>;
			dma-coherent;
		};

		usb0:usb@0 {
			status = "disabled";
			compatible = "intel,lgm-dwc3";
			#address-cells = <1>;
			#size-cells = <1>;
			ranges;
			dma-coherent;
			clocks = <&cgu0 LGM_GCLK_USB1>;
			dwc3@e7d00000 {
				compatible = "snps,dwc3";
				reg = <0xe7d00000 0x10000>;
				interrupt-parent = <&ioapic1>;
				interrupts = <47 1>;
				dr_mode = "host";
				usb-phy = <&usb0_phy>;
			};
	        };

		usb0_phy:usb-phy@e7e00000 {
			status = "disabled";
			compatible ="intel,lgm-usb-phy";
			reg = <0xe7e00000 0x10000>;
			interrupt-parent = <&ioapic1>;
			interrupts = <46 1>;
			power-domains = <&pd_usb1>;
			resets = <&rcu0 0x70 22>, <&rcu0 0x70 26>,
				 <&rcu0 0x70 24>, <&rcu0 0x70 28>;
			reset-names = "ctrl", "apb", "phy", "phy31";
			#phy-cells = <0>;
		};

		usb1:usb@1 {
			status = "disabled";
			compatible = "intel,lgm-dwc3";
			#address-cells = <1>;
			#size-cells = <1>;
			ranges;
			dma-coherent;
			clocks = <&cgu0 LGM_GCLK_USB2>;
			dwc3@e6e00000 {
				compatible = "snps,dwc3";
				reg = <0xe6e00000 0x10000>;
				interrupt-parent = <&ioapic1>;
				interrupts = <49 1>;
				dr_mode = "host";
				usb-phy = <&usb1_phy>;
			};
		};

		usb1_phy:usb-phy@e6f00000 {
			status = "disabled";
			compatible ="intel,lgm-usb-phy";
			reg = <0xe6f00000 0x10000>;
			interrupt-parent = <&ioapic1>;
			interrupts = <48 1>;
			power-domains = <&pd_usb2>;
			resets = <&rcu0 0x70 23>, <&rcu0 0x70 27>,
				<&rcu0 0x70 25>, <&rcu0 0x70 29>;
			reset-names = "ctrl", "apb", "phy", "phy31";
			#phy-cells = <0>;
		};

		i2c0: i2c@e0500000 {
			compatible = "mxl,lgm-i2c";
			#address-cells = <1>;
			#size-cells = <0>;
			reg = <0xe0500000 0x100>;
			interrupt-parent = <&ioapic1>;
			interrupts = <41 1>;
			clocks =  <&cgu0 LGM_CLK_OSC>;
			clock-frequency = <400000>;
			i2c-sda-hold-time-ns = <400>;
			resets = <&rcu0 0x40 1>;
			pinctrl-names = "default";
			pinctrl-0 = <&pinctrl_i2c0>;
		};

		i2c1: i2c@e1300000 {
			status = "disabled";
			compatible = "snps,designware-i2c";
			#address-cells = <1>;
			#size-cells = <0>;
			reg = <0xe1300000 0x100>;
			interrupt-parent = <&ioapic1>;
			interrupts = <73 1>;
			clocks =  <&cgu0 LGM_CLK_NOC4>;
			clock-names = "freq", "i2c";
			clock-frequency = <100000>;
			i2c-sda-hold-time-ns = <500>;
			resets = <&rcu0 0x30 9>;
			power-domains = <&pd_i2c1>;
			pinctrl-names = "default";
			pinctrl-0 = <&pinctrl_i2c1>;
		};

		i2c2: i2c@e1f00000 {
			status = "disabled";
			compatible = "snps,designware-i2c";
			#address-cells = <1>;
			#size-cells = <0>;
			reg = <0xe1f00000 0x100>;
			interrupt-parent = <&ioapic1>;
			interrupts = <74 1>;
			clocks =  <&cgu0 LGM_CLK_NOC4>;
			clock-names = "freq", "i2c";
			clock-frequency = <100000>;
			i2c-sda-hold-time-ns = <500>;
			resets = <&rcu0 0x30 10>;
			power-domains = <&pd_i2c2>;
			pinctrl-names = "default";
			pinctrl-0 = <&i2c2_pon>;
		};

		i2c3: i2c@e2000000 {
			status = "disabled";
			compatible = "snps,designware-i2c";
			#address-cells = <1>;
			#size-cells = <0>;
			reg = <0xe2000000 0x100>;
			interrupt-parent = <&ioapic1>;
			interrupts = <75 1>;
			clocks =  <&cgu0 LGM_CLK_NOC4>;
			clock-names = "freq", "i2c";
			clock-frequency = <100000>;
			i2c-sda-hold-time-ns = <500>;
			resets = <&rcu0 0x30 11>;
			power-domains = <&pd_i2c3>;
			pinctrl-names = "default";
			pinctrl-0 = <&i2c3_sfp>;
		};

		ssc0: spi@e0800000 {
			compatible = "intel,lgm-spi";
			reg = <0xe0800000 0x400>;
			interrupt-parent = <&ioapic1>;
			interrupts = <35 1>;
			interrupt-names = "spi_irq";
			#address-cells = <1>;
			#size-cells = <0>;
			clocks = <&cgu0 LGM_CLK_NOC4>, <&cgu0 LGM_GCLK_SSC0>;
			clock-names = "freq", "gate";
			bits-per-word = <32>;
			max-polling-time = <30>;
			base-cs = <0>;
			num-cs = <3>;
			power-domains = <&pd_ssc0>;
		};

		ssc1: spi@e0900000 {
			compatible = "intel,lgm-spi";
			reg = <0xe0900000 0x400>;
			interrupt-parent = <&ioapic1>;
			interrupts = <115 1>;
			interrupt-names = "spi_irq";
			#address-cells = <1>;
			#size-cells = <0>;
			clocks = <&cgu0 LGM_CLK_NOC4>, <&cgu0 LGM_GCLK_SSC1>;
			clock-names = "freq", "gate";
			bits-per-word = <32>;
			max-polling-time = <30>;
			base-cs = <0>;
			num-cs = <6>;
			power-domains = <&pd_ssc1>;
		};

		pwm: pwm@e0d00000 {
			compatible = "intel,lgm-pwm";
			reg = <0xe0d00000 0x30>;
			#pwm-cells = <2>;
			clocks = <&cgu0 LGM_GCLK_PWM>;
			resets = <&rcu0 0x30 21>;
		};

		fan0: pwm-fan {
			status = "disabled";
			compatible = "pwm-fan";
		};

		ssc2: spi@e1d00000 {
			compatible = "intel,lgm-spi";
			reg = <0xe1d00000 0x400>;
			interrupt-parent = <&ioapic1>;
			interrupts = <71 1>;
			interrupt-names = "spi_irq";
			#address-cells = <1>;
			#size-cells = <1>;
			clocks = <&cgu0 LGM_CLK_NOC4>, <&cgu0 LGM_GCLK_SSC2>;
			clock-names = "freq", "gate";
			bits-per-word = <32>;
			max-polling-time = <30>;
			base-cs = <0>;
			num-cs = <3>;
			status = "disabled";
			power-domains = <&pd_ssc2>;
		};

		ssc3: spi@e1e00000 {
			compatible = "intel,lgm-spi";
			reg = <0xe1e00000 0x400>;
			interrupt-parent = <&ioapic1>;
			interrupts = <72 1>;
			interrupt-names = "spi_irq";
			#address-cells = <1>;
			#size-cells = <1>;
			clocks = <&cgu0 LGM_CLK_NOC4>, <&cgu0 LGM_GCLK_SSC3>;
			clock-names = "freq", "gate";
			pinctrl-names = "default";
			bits-per-word = <32>;
			max-polling-time = <30>;
			base-cs = <0>;
			num-cs = <2>;
			status = "disabled";
			power-domains = <&pd_ssc3>;
		};

		dma2tx: dma@e7000000 {
			compatible = "intel,lgm-dma2tx";
			reg = <0xe7000000 0x1000>;
			clocks = <&cgu0 LGM_GCLK_IDMAT2>;
			resets = <&rcu0 0x70 3>;
			#dma-cells = <1>;
			intel,dma-poll-cnt = <2>;
			mxl,dma-rs-pool = <0 8>, <1 8>, <2 8>, <3 8>, <4 8>, <5 8>, <6 8>, <7 8>, <8 8>, <9 8>, <10 0>, <11 0>, <12 0>, <13 0>, <14 0>, <15 0>;
			ldma,channels {
				#size-cells = <0>;
				#address-cells = <1>;
				dma-channels@0 {
						reg = <0>;
						chan,hdr-mode = <192 0>;
				};
				dma-channels@1 {
						reg = <1>;
						chan,hdr-mode = <192 0>;
				};
				dma-channels@2 {
						reg = <2>;
						chan,hdr-mode = <192 0>;
				};
				dma-channels@3 {
						reg = <3>;
						chan,hdr-mode = <192 0>;
				};
				dma-channels@4 {
						reg = <4>;
						chan,hdr-mode = <192 0>;
				};
				dma-channels@5 {
						reg = <5>;
						chan,hdr-mode = <192 0>;
				};
				dma-channels@6 {
						reg = <6>;
						chan,hdr-mode = <192 0>;
				};
				dma-channels@7 {
						reg = <7>;
						chan,hdr-mode = <192 0>;
				};
				dma-channels@8 {
						reg = <8>;
						chan,hdr-mode = <192 0>;
				};
				dma-channels@9 {
						reg = <9>;
						chan,hdr-mode = <192 0>;
				};
				dma-channels@10 {
						reg = <10>;
						chan,hdr-mode = <192 0>;
				};
				dma-channels@11 {
						reg = <11>;
						chan,hdr-mode = <192 0>;
				};
				dma-channels@12 {
						reg = <12>;
						chan,hdr-mode = <192 0>;
				};
				dma-channels@13 {
						reg = <13>;
						chan,hdr-mode = <192 0>;
				};
				dma-channels@14 {
						reg = <14>;
						chan,hdr-mode = <192 0>;
				};
				dma-channels@15 {
						reg = <15>;
						chan,hdr-mode = <192 0>;
				};
			};
		};

		dma1rx: dma@e7200000 {
			compatible = "intel,lgm-dma1rx";
			reg = <0xe7200000 0x1000>;
			clocks = <&cgu0 LGM_GCLK_IDMAR1>;
			resets = <&rcu0 0x70 0>;
			#dma-cells = <1>;
			intel,dma-poll-cnt = <8>;
			intel,dma-dburst-wr;
		};

		dma1tx: dma@e7300000 {
			compatible = "intel,lgm-dma1tx";
			reg = <0xe7300000 0x1000>;
			clocks = <&cgu0 LGM_GCLK_IDMAT1>;
			resets = <&rcu0 0x70 2>;
			#dma-cells = <1>;
			intel,dma-poll-cnt = <2>;
			mxl,dma-rs-pool = <0 8>, <1 8>, <2 8>, <3 8>, <4 8>, <5 8>, <6 8>, <7 8>, <8 8>, <9 8>, <10 0>, <11 0>, <12 0>, <13 0>, <14 0>, <15 0>;
			ldma,channels {
				#size-cells = <0>;
				#address-cells = <1>;
				dma-channels@0 {
						reg = <0>;
						chan,hdr-mode = <192 0>;
				};
				dma-channels@1 {
						reg = <1>;
						chan,hdr-mode = <192 0>;
				};
				dma-channels@2 {
						reg = <2>;
						chan,hdr-mode = <192 0>;
				};
				dma-channels@3 {
						reg = <3>;
						chan,hdr-mode = <192 0>;
				};
				dma-channels@4 {
						reg = <4>;
						chan,hdr-mode = <192 0>;
				};
				dma-channels@5 {
						reg = <5>;
						chan,hdr-mode = <192 0>;
				};
				dma-channels@6 {
						reg = <6>;
						chan,hdr-mode = <192 0>;
				};
				dma-channels@7 {
						reg = <7>;
						chan,hdr-mode = <192 0>;
				};
				dma-channels@8 {
						reg = <8>;
						chan,hdr-mode = <192 0>;
				};
				dma-channels@9 {
						reg = <9>;
						chan,hdr-mode = <192 0>;
				};
				dma-channels@10 {
						reg = <10>;
						chan,hdr-mode = <192 0>;
				};
				dma-channels@11 {
						reg = <11>;
						chan,hdr-mode = <192 0>;
				};
				dma-channels@12 {
						reg = <12>;
						chan,hdr-mode = <192 0>;
				};
				dma-channels@13 {
						reg = <13>;
						chan,hdr-mode = <192 0>;
				};
				dma-channels@14 {
						reg = <14>;
						chan,hdr-mode = <192 0>;
				};
				dma-channels@15 {
						reg = <15>;
						chan,hdr-mode = <192 0>;
				};
			};
		};

		dma0tx: dma@e7700000 {
			compatible = "intel,lgm-dma0tx";
			reg = <0xe7700000 0x1000>;
			clocks = <&cgu0 LGM_GCLK_IDMAT0>;
			resets = <&rcu0 0x70 1>;
			#dma-cells = <1>;
			intel,dma-poll-cnt = <2>;
			intel,dma-byte-en;
			mxl,dma-rs-pool = <0 8>, <1 8>, <2 8>, <3 8>, <4 8>, <5 8>, <6 8>, <7 8>, <8 8>, <9 8>, <10 0>, <11 0>, <12 0>, <13 0>, <14 0>, <15 0>;
			ldma,channels {
				#size-cells = <0>;
				#address-cells = <1>;
				dma-channels@0 {
						reg = <0>;
						chan,hdr-mode = <192 0>;
				};
				dma-channels@1 {
						reg = <1>;
						chan,hdr-mode = <192 0>;
				};
				dma-channels@2 {
						reg = <2>;
						chan,hdr-mode = <192 0>;
				};
				dma-channels@3 {
						reg = <3>;
						chan,hdr-mode = <192 0>;
				};
				dma-channels@4 {
						reg = <4>;
						chan,hdr-mode = <192 0>;
				};
				dma-channels@5 {
						reg = <5>;
						chan,hdr-mode = <192 0>;
				};
				dma-channels@6 {
						reg = <6>;
						chan,hdr-mode = <192 0>;
				};
				dma-channels@7 {
						reg = <7>;
						chan,hdr-mode = <192 0>;
				};
				dma-channels@8 {
						reg = <8>;
						chan,hdr-mode = <192 0>;
				};
				dma-channels@9 {
						reg = <9>;
						chan,hdr-mode = <192 0>;
				};
				dma-channels@10 {
						reg = <10>;
						chan,hdr-mode = <192 0>;
				};
				dma-channels@11 {
						reg = <11>;
						chan,hdr-mode = <192 0>;
				};
				dma-channels@12 {
						reg = <12>;
						chan,hdr-mode = <192 0>;
				};
				dma-channels@13 {
						reg = <13>;
						chan,hdr-mode = <192 1>;
				};
				dma-channels@14 {
						reg = <14>;
						chan,hdr-mode = <192 0>;
				};
				dma-channels@15 {
						reg = <15>;
						chan,hdr-mode = <192 0>;
				};
			};
		};

		dma3: dma@ec800000 {
			compatible = "intel,lgm-dma3";
			reg = <0xec800000 0x1000>;
			clocks = <&cgu0 LGM_GCLK_DMA3>;
			resets = <&rcu0 0x10 9>;
			#dma-cells = <1>;
			dma-coherent;
			intel,dma-poll-cnt = <4>;
			intel,dma-byte-en;
			intel,dma-dburst-wr;
			ldma,channels {
				#size-cells = <0>;
				#address-cells = <1>;
				dma-channels@0 {
					reg = <0>;
					chan,hw-desc = <0x600 2>;
				};
				dma-channels@1 {
					reg = <1>;
					chan,hw-desc = <0x620 2>;
				};
				dma-channels@2 {
					reg = <2>;
					chan,hw-desc = <0x700 2>;
				};
				dma-channels@3 {
					reg = <3>;
					chan,hw-desc = <0x720 2>;
				};
				dma-channels@4 {
					reg = <4>;
					chan,hw-desc = <0x800 2>;
				};
				dma-channels@5 {
					reg = <5>;
					chan,hw-desc = <0x820 2>;
				};
				dma-channels@6 {
					reg = <6>;
					chan,hw-desc = <0x900 2>;
				};
				dma-channels@7 {
					reg = <7>;
					chan,hw-desc = <0x920 2>;
				};
				dma-channels@8 {
					reg = <8>;
					chan,hw-desc = <0xa00 2>;
				};
				dma-channels@9 {
					reg = <9>;
					chan,hw-desc = <0xa20 2>;
				};
				dma-channels@10 {
					reg = <10>;
					chan,hw-desc = <0xb00 2>;
				};
				dma-channels@11 {
					reg = <11>;
					chan,hw-desc = <0xb20 2>;
				};
				dma-channels@12 {
					reg = <12>;
					chan,hw-desc = <0xc00 2>;
				};
				dma-channels@13 {
					reg = <13>;
					chan,hw-desc = <0xc20 2>;
				};
				dma-channels@14 {
					reg = <14>;
					chan,hw-desc = <0xd00 2>;
				};
				dma-channels@15 {
					reg = <15>;
					chan,hw-desc = <0xd20 2>;
				};

			};
		};

		toe_dma30: dma@ec900000 {
			compatible = "intel,lgm-toe-dma30";
			reg = <0xec900000 0x1000>;
			#dma-cells = <3>;
			intel,dma-poll-cnt = <4>;
			intel,dma-byte-en;
			intel,dma-dburst-wr;
			ldma,channels {
				#size-cells = <0>;
				#address-cells = <1>;
				dma-channels@4 {
					reg = <4>;
					chan,hw-desc = <0xecb40600 2>;
				};
				dma-channels@5 {
					reg = <5>;
					chan,hw-desc = <0xecb40620 2>;
				};
				dma-channels@8 {
					reg = <8>;
					chan,hw-desc = <0xecb41000 1>;
					chan,desc-rx-nonpost;
				};
				dma-channels@9 {
					reg = <9>;
					chan,hw-desc = <0xecb41100 2>;
				};
				dma-channels@10 {
					reg = <10>;
					chan,hw-desc = <0xecb41200 1>;
					chan,desc-rx-nonpost;
				};
				dma-channels@11 {
					reg = <11>;
					chan,hw-desc = <0xecb41300 2>;
				};
				dma-channels@6 {
					reg = <6>;
					chan,hw-desc = <0xecb40800 2>;
				};
				dma-channels@7 {
					reg = <7>;
					chan,hw-desc = <0xecb40820 2>;
				};
				dma-channels@18 {
					reg = <18>;
					chan,hw-desc = <0xecb41400 1>;
					chan,desc-rx-nonpost;
				};
				dma-channels@19 {
					reg = <19>;
					chan,hw-desc = <0xecb41500 2>;
				};
				dma-channels@20 {
					reg = <20>;
					chan,hw-desc = <0xecb41600 1>;
					chan,desc-rx-nonpost;
				};
				dma-channels@21 {
					reg = <21>;
					chan,hw-desc = <0xecb41700 2>;
				};
				dma-channels@14 {
					reg = <14>;
					chan,hw-desc = <0xecb40a00 2>;
				};
				dma-channels@15 {
					reg = <15>;
					chan,hw-desc = <0xecb40a20 2>;
				};
				dma-channels@28 {
					reg = <28>;
					chan,hw-desc = <0xecb41800 1>;
					chan,desc-rx-nonpost;
				};
				dma-channels@29 {
					reg = <29>;
					chan,hw-desc = <0xecb41900 2>;
				};
				dma-channels@30 {
					reg = <30>;
					chan,hw-desc = <0xecb41a00 1>;
					chan,desc-rx-nonpost;
				};
				dma-channels@31 {
					reg = <31>;
					chan,hw-desc = <0xecb41b00 2>;
				};
				dma-channels@16 {
					reg = <16>;
					chan,hw-desc = <0xecb40c00 2>;
				};
				dma-channels@17 {
					reg = <17>;
					chan,hw-desc = <0xecb40c20 2>;
				};
				dma-channels@22 {
					reg = <22>;
					chan,hw-desc = <0xecb41c00 1>;
					chan,desc-rx-nonpost;
				};
				dma-channels@23 {
					reg = <23>;
					chan,hw-desc = <0xecb41d00 2>;
				};
				dma-channels@24 {
					reg = <24>;
					chan,hw-desc = <0xecb41e00 1>;
					chan,desc-rx-nonpost;
				};
				dma-channels@25 {
					reg = <25>;
					chan,hw-desc = <0xecb41f00 2>;
				};
			};
		};

		toe_dma31: dma@eca00000 {
			compatible = "intel,lgm-toe-dma31";
			reg = <0xeca00000 0x1000>;
			#dma-cells = <3>;
			intel,dma-poll-cnt = <4>;
			intel,dma-byte-en;
			intel,dma-dburst-wr;
			ldma,channels {
				#size-cells = <0>;
				#address-cells = <1>;
				dma-channels@4 {
					reg = <4>;
					chan,hw-desc = <0xecb40700 2>;
				};
				dma-channels@5 {
					reg = <5>;
					chan,hw-desc = <0xecb40720 2>;
				};
				dma-channels@8 {
					reg = <8>;
					chan,hw-desc = <0xecb42000 1>;
					chan,desc-rx-nonpost;
				};
				dma-channels@9 {
					reg = <9>;
					chan,hw-desc = <0xecb42100 2>;
				};
				dma-channels@10 {
					reg = <10>;
					chan,hw-desc = <0xecb42200 1>;
					chan,desc-rx-nonpost;
				};
				dma-channels@11 {
					reg = <11>;
					chan,hw-desc = <0xecb42300 2>;
				};
				dma-channels@6 {
					reg = <6>;
					chan,hw-desc = <0xecb40900 2>;
				};
				dma-channels@7 {
					reg = <7>;
					chan,hw-desc = <0xecb40920 2>;
				};
				dma-channels@18 {
					reg = <18>;
					chan,hw-desc = <0xecb42400 1>;
					chan,desc-rx-nonpost;
				};
				dma-channels@19 {
					reg = <19>;
					chan,hw-desc = <0xecb42500 2>;
				};
				dma-channels@20 {
					reg = <20>;
					chan,hw-desc = <0xecb42600 1>;
					chan,desc-rx-nonpost;
				};
				dma-channels@21 {
					reg = <21>;
					chan,hw-desc = <0xecb42700 2>;
				};
				dma-channels@14 {
					reg = <14>;
					chan,hw-desc = <0xecb40b00 2>;
				};
				dma-channels@15 {
					reg = <15>;
					chan,hw-desc = <0xecb40b20 2>;
				};
				dma-channels@28 {
					reg = <28>;
					chan,hw-desc = <0xecb42800 1>;
					chan,desc-rx-nonpost;
				};
				dma-channels@29 {
					reg = <29>;
					chan,hw-desc = <0xecb42900 2>;
				};
				dma-channels@30 {
					reg = <30>;
					chan,hw-desc = <0xecb42a00 1>;
					chan,desc-rx-nonpost;
				};
				dma-channels@31 {
					reg = <31>;
					chan,hw-desc = <0xecb42b00 2>;
				};
				dma-channels@16 {
					reg = <16>;
					chan,hw-desc = <0xecb40d00 2>;
				};
				dma-channels@17 {
					reg = <17>;
					chan,hw-desc = <0xecb40d20 2>;
				};
				dma-channels@22 {
					reg = <22>;
					chan,hw-desc = <0xecb42c00 1>;
					chan,desc-rx-nonpost;
				};
				dma-channels@23 {
					reg = <23>;
					chan,hw-desc = <0xecb42d00 2>;
				};
				dma-channels@24 {
					reg = <24>;
					chan,hw-desc = <0xecb42e00 1>;
					chan,desc-rx-nonpost;
				};
				dma-channels@25 {
					reg = <25>;
					chan,hw-desc = <0xecb42f00 2>;
				};
			};
		};

		mcpy: mcpy@ed700000 {
			compatible = "intel,lgm-mcpy";
			reg = <0xed700000 0x10000>;
			clocks = <&cgu0 LGM_CLK_NGI>;
			clock-names = "freq";
			interrupt-parent = <&soc_msi>;
			interrupts = <36>, <37>, <38>, <39>,
				     <40>, <41>, <42>, <43>;
			dmas = <&dma3 0>, <&dma3 1>, <&dma3 2>, <&dma3 3>,
			       <&dma3 4>, <&dma3 5>, <&dma3 6>, <&dma3 7>,
			       <&dma3 8>, <&dma3 9>, <&dma3 10>, <&dma3 11>,
			       <&dma3 12>, <&dma3 13>, <&dma3 14>, <&dma3 15>;
			dma-names = "p0rx", "p0tx", "p1rx", "p1tx",
				    "p2rx", "p2tx", "p3rx", "p3tx",
				    "p4rx", "p4tx", "p5rx", "p5tx",
				    "p6rx", "p6tx", "p7rx", "p7tx";
			intel,mcpy-portnum = <8>;
			intel,mcpy-maxchksz = <3>;
			power-domains = <&pd_toe>;
		};

		sram: sram@ecd00000 {
			compatible = "mmio-sram";
			reg = <0xecd00000 0x80000>;
			#address-cells = <1>;
			#size-cells = <1>;
			ranges = <0 0xecd00000 0x80000>;

	        	cqm_sram: cqm_sram {
				reg = <0x0 0xe900>;
				pool;
			};

			toe_sram: toe_sram {
				reg = <0xe900 0x71700>;
				pool;
			};
		};

		/* pip-enc on pcie10 */
		pip_enc0: pip_enc@0xd0a80000 {
			compatible = "mxl,lgm-pip-enc";
			reg = <0xd0a80000 0x80000>;
			reg-names = "pip-enc-memory";
			interrupt-parent = <&ioapic1>;
			interrupts = <96 1>, <97 1>, <98 1>;
			interrupt-names = "crypto-ip", "rd-rsp-key-exp", "wr-key-exp";
			status = "disabled";
		};

		pcie10:pcie@d0e00000 {
			status = "disabled";
			compatible = "intel,lgm-pcie";
			device_type = "pci";
			#address-cells = <3>;
			#size-cells = <2>;
			reg = <
				0xd0e00000 0x1000 /* RC controller DBI */
				0xd0ec0000 0x1000 /* RC controller ATU */
				0xd2000000 0x20000 /* Cfg */
				0xd0a41000 0x1000 /* App logic */
			>;
			reg-names = "dbi", "atu", "config", "app";
			linux,pci-domain = <0>;
			max-link-speed = <4>;
			bus-range = <0x00 0x08>;
			interrupt-parent = <&ioapic1>;
			interrupts = <67 1>;
			interrupt-names = "ir";
			#interrupt-cells = <1>;
			interrupt-map-mask = <0 0 0 0x7>;
			interrupt-map = <0 0 0 1 &ioapic1 27 1>,
					<0 0 0 2 &ioapic1 28 1>,
					<0 0 0 3 &ioapic1 29 1>,
					<0 0 0 4 &ioapic1 30 1>;
			ranges = <0x02000000 0 0xd4000000 0xd4000000 0 0x04000000    /* Non-pretechable memory 32bit */
				 >;
			resets = <&rcu0 0x50 0>;
			reset-names =  "core";
			intel,pcie-syscon = <&sysconf>;
			intel,has_iatu;
			clocks = <&cgu0 LGM_GCLK_PCIE10>;
			clock-names ="ctl";
			phys = <&cb0phy0 PHY_TYPE_PCIE_SL>;
			phy-names = "pcie";
		};

		pcie11:pcie@d0f00000 {
			status = "disabled";
			compatible = "intel,lgm-pcie";
			device_type = "pci";
			#address-cells = <3>;
			#size-cells = <2>;
			reg = <
				0xd0f00000 0x1000 /* RC controller DBI */
				0xd0fc0000 0x1000 /* RC controller ATU */
				0xd2800000 0x20000 /* Cfg */
				0xd0b41000 0x1000 /* App logic */
			>;
			reg-names = "dbi", "atu", "config", "app";
			linux,pci-domain = <1>;
			max-link-speed = <4>;
			bus-range = <0x00 0x08>;
			interrupt-parent = <&ioapic1>;
			interrupts = <143 1>;
			interrupt-names = "ir";
			#interrupt-cells = <1>;
			interrupt-map-mask = <0 0 0 0x7>;
			interrupt-map = <0 0 0 1 &ioapic1 76 1>,
					<0 0 0 2 &ioapic1 77 1>,
					<0 0 0 3 &ioapic1 78 1>,
					<0 0 0 4 &ioapic1 79 1>;
			ranges = <0x02000000 0 0xd8000000 0xd8000000 0 0x04000000    /* Non-pretechable memory 32bit */
				 >;
			resets = <&rcu0 0x50 1>;
			reset-names =  "core";
			intel,pcie-syscon = <&sysconf>;
			intel,has_iatu;
			clocks = <&cgu0 LGM_GCLK_PCIE11>;
			clock-names ="ctl";
			phys = <&cb0phy1 PHY_TYPE_PCIE_SL>;
			phy-names = "pcie";
		};

		pcie30:pcie@d1000000 {
			status = "disabled";
			compatible = "intel,lgm-pcie";
			device_type = "pci";
			#address-cells = <3>;
			#size-cells = <2>;
			reg = <
				0xd1000000 0x1000 /* RC controller DBI */
				0xd10c0000 0x1000 /* RC controller ATU */
				0xd3000000 0x20000 /* Cfg */
				0xd0c41000 0x1000 /* App logic */
			>;
			reg-names = "dbi", "atu", "config", "app";
			linux,pci-domain = <2>;
			max-link-speed = <3>;
			bus-range = <0x00 0x08>;
			interrupt-parent = <&ioapic1>;
			interrupts = <146 1>;
			interrupt-names = "ir";
			#interrupt-cells = <1>;
			interrupt-map-mask = <0 0 0 0x7>;
			interrupt-map = <0 0 0 1 &ioapic1 216 1>,
					<0 0 0 2 &ioapic1 217 1>,
					<0 0 0 3 &ioapic1 218 1>,
					<0 0 0 4 &ioapic1 219 1>;
			ranges = <0x02000000 0 0xdc000000 0xdc000000 0 0x02000000    /* Non-pretechable memory 32bit */
				 >;
			resets = <&rcu0 0x50 2>;
			reset-names =  "core";
			intel,pcie-syscon = <&sysconf>;
			intel,has_iatu;
			clocks = <&cgu0 LGM_GCLK_PCIE30>;
			clock-names ="ctl";
			phys = <&cb1phy0 PHY_TYPE_PCIE_SL>;
			phy-names = "pcie";
		};

		pcie31:pcie@d1100000 {
			status = "disabled";
			compatible = "intel,lgm-pcie";
			device_type = "pci";
			#address-cells = <3>;
			#size-cells = <2>;
			reg = <
				0xd1100000 0x1000 /* RC controller DBI */
				0xd11c0000 0x1000 /* RC controller ATU */
				0xd3800000 0x20000 /* Cfg */
				0xd0d41000 0x1000 /* App logic */
			>;
			reg-names = "dbi", "atu", "config", "app";
			linux,pci-domain = <3>;
			max-link-speed = <3>;
			bus-range = <0x00 0x08>;
			interrupt-parent = <&ioapic1>;
			interrupts = <147 1>;
			interrupt-names = "ir";
			#interrupt-cells = <1>;
			interrupt-map-mask = <0 0 0 0x7>;
			interrupt-map = <0 0 0 1 &ioapic1 220 1>,
					<0 0 0 2 &ioapic1 221 1>,
					<0 0 0 3 &ioapic1 222 1>,
					<0 0 0 4 &ioapic1 223 1>;
			ranges = <0x02000000 0 0xde000000 0xde000000 0 0x02000000    /* Non-pretechable memory 32bit */
				 >;
			resets = <&rcu0 0x50 3>;
			reset-names =  "core";
			intel,pcie-syscon = <&sysconf>;
			intel,has_iatu;
			clocks = <&cgu0 LGM_GCLK_PCIE31>;
			clock-names ="ctl";
			phys = <&cb1phy1 PHY_TYPE_PCIE_SL>;
			phy-names = "pcie";
		};

		/* pip-enc on pcie20 */
		pip_enc1: pip_enc@0xc0a80000 {
			compatible = "mxl,lgm-pip-enc";
			reg = <0xc0a80000 0x80000>;
			reg-names = "pip-enc-memory";
			interrupt-parent = <&ioapic1>;
			interrupts = <178 1>, <179 1>, <180 1>;
			interrupt-names = "crypto-ip", "rd-rsp-key-exp", "wr-key-exp";
			status = "disabled";
		};

		pcie20:pcie@c0e00000 {
			status = "disabled";
			compatible = "intel,lgm-pcie";
			device_type = "pci";
			#address-cells = <3>;
			#size-cells = <2>;
			reg = <
				0xc0e00000 0x1000 /* RC controller DBI */
				0xc0ec0000 0x1000 /* RC controller ATU */
				0xc2000000 0x20000 /* Cfg */
				0xc0a41000 0x1000 /* App logic */
			>;
			reg-names = "dbi", "atu", "config", "app";
			linux,pci-domain = <4>;
			max-link-speed = <4>;
			bus-range = <0x00 0x08>;
			interrupt-parent = <&ioapic1>;
			interrupts = <144 1>;
			interrupt-names = "ir";
			#interrupt-cells = <1>;
			interrupt-map-mask = <0 0 0 0x7>;
			interrupt-map = <0 0 0 1 &ioapic1 116 1>,
					<0 0 0 2 &ioapic1 117 1>,
					<0 0 0 3 &ioapic1 118 1>,
					<0 0 0 4 &ioapic1 119 1>;
			ranges = <0x02000000 0 0xc4000000 0xc4000000 0 0x04000000    /* Non-pretechable memory 32bit */
				 >;
			resets = <&rcu0 0x60 0>;
			reset-names =  "core";
			intel,pcie-syscon = <&sysconf>;
			intel,has_bus_iatu;
			clocks = <&cgu0 LGM_GCLK_PCIE20>;
			clock-names ="ctl";
			phys = <&cb2phy0 PHY_TYPE_PCIE_SL>;
			phy-names = "pcie";
		};

		pcie21:pcie@c0f00000 {
			status = "disabled";
			compatible = "intel,lgm-pcie";
			device_type = "pci";
			#address-cells = <3>;
			#size-cells = <2>;
			reg = <
				0xc0f00000 0x1000 /* RC controller DBI */
				0xc0fc0000 0x1000 /* RC controller ATU */
				0xc2800000 0x20000 /* Cfg */
				0xc0b41000 0x1000 /* App logic */
			>;
			reg-names = "dbi", "atu", "config", "app";
			linux,pci-domain = <5>;
			max-link-speed = <4>;
			bus-range = <0x00 0x08>;
			interrupt-parent = <&ioapic1>;
			interrupts = <145 1>;
			interrupt-names = "ir";
			#interrupt-cells = <1>;
			interrupt-map-mask = <0 0 0 0x7>;
			interrupt-map = <0 0 0 1 &ioapic1 120 1>,
					<0 0 0 2 &ioapic1 121 1>,
					<0 0 0 3 &ioapic1 122 1>,
					<0 0 0 4 &ioapic1 123 1>;
			ranges = <0x02000000 0 0xc8000000 0xc8000000 0 0x04000000    /* Non-pretechable memory 32bit */
				 >;
			resets = <&rcu0 0x60 1>;
			reset-names =  "core";
			intel,pcie-syscon = <&sysconf>;
			intel,has_bus_iatu;
			clocks = <&cgu0 LGM_GCLK_PCIE21>;
			clock-names ="ctl";
			phys = <&cb2phy1 PHY_TYPE_PCIE_SL>;
			phy-names = "pcie";
		};

		pcie40:pcie@c1000000 {
			status = "disabled";
			compatible = "intel,lgm-pcie";
			device_type = "pci";
			#address-cells = <3>;
			#size-cells = <2>;
			reg = <
				0xc1000000 0x1000 /* RC controller DBI */
				0xc10c0000 0x1000 /* RC controller ATU */
				0xc3000000 0x20000 /* Cfg */
				0xc0c41000 0x1000 /* App logic */
			>;
			reg-names = "dbi", "atu", "config", "app";
			linux,pci-domain = <6>;
			max-link-speed = <3>;
			bus-range = <0x00 0x08>;
			interrupt-parent = <&ioapic1>;
			interrupts = <148 1>;
			interrupt-names = "ir";
			#interrupt-cells = <1>;
			interrupt-map-mask = <0 0 0 0x7>;
			interrupt-map = <0 0 0 1 &ioapic1 224 1>,
					<0 0 0 2 &ioapic1 225 1>,
					<0 0 0 3 &ioapic1 226 1>,
					<0 0 0 4 &ioapic1 227 1>;
			ranges = <0x02000000 0 0xcc000000 0xcc000000 0 0x02000000    /* Non-pretechable memory 32bit */
				 >;
			resets = <&rcu0 0x60 2>;
			reset-names =  "core";
			intel,pcie-syscon = <&sysconf>;
			intel,has_bus_iatu;
			clocks = <&cgu0 LGM_GCLK_PCIE40>;
			clock-names ="ctl";
			phys = <&cb3phy0 PHY_TYPE_PCIE_SL>;
			phy-names = "pcie";
		};

		pcie41:pcie@c1100000 {
			status = "disabled";
			compatible = "intel,lgm-pcie";
			device_type = "pci";
			#address-cells = <3>;
			#size-cells = <2>;
			reg = <
				0xc1100000 0x1000 /* RC controller DBI */
				0xc11c0000 0x1000 /* RC controller DBI */
				0xc3800000 0x20000 /* Cfg */
				0xc0d41000 0x1000 /* App logic */
			>;
			reg-names = "dbi", "atu", "config", "app";
			linux,pci-domain = <7>;
			max-link-speed = <3>;
			bus-range = <0x00 0x08>;
			interrupt-parent = <&ioapic1>;
			interrupts = <149 1>;
			interrupt-names = "ir";
			#interrupt-cells = <1>;
			interrupt-map-mask = <0 0 0 0x7>;
			interrupt-map = <0 0 0 1 &ioapic1 228 1>,
					<0 0 0 2 &ioapic1 229 1>,
					<0 0 0 3 &ioapic1 230 1>,
					<0 0 0 4 &ioapic1 231 1>;
			ranges = <0x02000000 0 0xce000000 0xce000000 0 0x02000000    /* Non-pretechable memory 32bit */
				 >;
			resets = <&rcu0 0x60 3>;
			reset-names =  "core";
			intel,pcie-syscon = <&sysconf>;
			intel,has_bus_iatu;
			clocks = <&cgu0 LGM_GCLK_PCIE41>;
			clock-names ="ctl";
			phys = <&cb3phy1 PHY_TYPE_PCIE_SL>;
			phy-names = "pcie";
		};

		sdxc: sdhci@ec600000 {
			status = "disabled";
			compatible = "intel,lgm-sdhci-5.1-sdxc";
			reg = <0xec600000 0x300>;
			interrupt-parent = <&ioapic1>;
			interrupts = <43 1>;
			clocks = <&cgu0 LGM_CLK_SDXC>, <&cgu0 LGM_GCLK_SDXC>;
			clock-names = "clk_xin", "clk_ahb";
			clock-output-names = "sdxc_cardclock", "sdxc_sampleclock";
			#clock-cells = <1>;
			arasan,soc-ctl-syscon = <&sysconf>;
			dma-coherent;
			clk-phase-sd-hs = <0>, <180>;
			clk-phase-uhs-sdr50 = <0>, <180>;
			clk-phase-uhs-sdr104 = <0>, <180>;
			power-domains = <&pd_sdxc>;
		};

		emmc: sdhci@ec700000 {
			status = "disabled";
			compatible = "intel,lgm-sdhci-5.1-emmc",
				     "arasan,sdhci-5.1";
			reg = <0xec700000 0x300>;
			interrupt-parent = <&ioapic1>;
			interrupts = <44 1>;
			clocks = <&cgu0 LGM_CLK_EMMC>, <&cgu0 LGM_GCLK_EMMC>;
			clock-names = "clk_xin", "clk_ahb";
			clock-frequency = <200000000>;
			clock-output-names = "emmc_cardclock", "emmc_sampleclock";
			#clock-cells = <1>;
			phys = <&emmc_phy>;
			phy-names = "phy_arasan";
			arasan,soc-ctl-syscon = <&sysconf>;
			dma-coherent;
			clk-phase-mmc-hs200 = <0>, <180>;
			clk-phase-mmc-hs400 = <0>, <90>;
			power-domains = <&pd_emmc>;
		};

		emmc_phy: emmc_phy {
			status = "disabled";
			compatible = "intel,lgm-emmc-phy";
			intel,syscon = <&sysconf>;
			clocks = <&emmc 0>;
			clock-names = "emmcclk";
			#phy-cells = <0>;
		};

		ebu_nand: nand-controller@e0f00000 {
			compatible = "intel,lgm-ebunand";
			reg = <0xe0f00000 0x100>,
			      <0xe1000000 0x300>,
			      <0xe1400000 0x80000>,
			      <0xe1c00000 0x10000>,
			      <0x17400000 0x4>,
			      <0x17c00000 0x4>;
			reg-names = "ebunand", "hsnand", "nand_cs1", "nand_cs0",
				    "addr_sel0", "addr_sel1";
			clocks = <&cgu0 LGM_GCLK_EBU>;
			dmas = <&dma0 8 4 8>, <&dma0 9 4 8>;
			dma-names = "rx", "tx";
			power-domains = <&pd_ebu>;
			dma-coherent;
			#address-cells = <1>;
			#size-cells = <0>;
		};

		chipid: chipid@ecc80000{
			compatible = "mxl,chipid";
			reg = <0xecc80000 0xc0>;
		};

		crypto: eip-197@ed600000 {
			compatible = "inside-secure,safexcel-eip197-mxl";
			#address-cells = <1>;
			#size-cells = <1>;
			interrupt-parent = <&ioapic1>;
			interrupts = <104 1>, <105 1>, <106 1>, <107 1>, <108 1>;
			interrupt-names = "mem", "ring0", "ring1",
				"ring2", "ring3";
			clock-names = "core";
			clocks = <&cgu0 LGM_GCLK_EIP197>;
			reg = <0xed600000 0x100000>;
			power-domains = <&pd_eip197>;
			dma-coherent;
		};

		dma0: dma@e0e00000 {
			compatible = "intel,lgm-cdma";
			reg = <0xe0e00000 0x1000>;
			#dma-cells = <3>;
			interrupt-parent = <&ioapic1>;
			interrupts = <82 1>;
			resets = <&rcu0 0x30 0>;
			clocks = <&cgu0 LGM_GCLK_DMA0>;
			intel,dma-poll-cnt = <4>;
			intel,dma-byte-en;
			intel,dma-drb = <1>;
			dma-coherent;
		};

		buffer_pool_size: bm_buffer_pool_size {
			mxl,bm-buff-pool-size = <0x100 0x200 0x400 0x800 0x2800>;
		};

		lpid_config: lpid_configuration {
			mxl,port-mode = <LPID_PORT_MODE1>;
			mxl,wan-mode = <LPID_WAN_ETH>;
			mxl,lpid-epg-map = <2 75 0 0>,
						<3 35 2 8>,
						<4 51 1 8>,
						<5 36 2 9>,
						<6 37 2 10>,
						<7 52 1 9>,
						<8 53 1 10>,
						<9 38 2 11>,
						<10 54 1 11>;
		};

		voice_c55_mem {
			#address-cells = <2>;
			#size-cells = <1>;
			voice_c55_ddr: voice_c55_ddr@c00c00000 {
				reg = < 0xc 0xc00000 0x200000 	 /* CQM buffer */
						0xc 0xe00000 0x200000 >; /* Voice FW   */
			};
		};

		cqm_lgm: cqm_lgm@e6000000 {
			compatible = "mxl,lgm-cqm";
			reg = < 0xe6000000 0x100000 /*CQM_DC_DESC_PORT*/
			0xe6400000 0x1000   /*CQM_WIB*/
			0xe6440000 0x800 /*CQM_QID2EP_MAP*/
			0xe6610000 0x10000 /*CQM_CONTROL*/
			0xe6620000 0x2000 /*CBM_QIDT0*/
			0xe6622000 0x2000 /*CBM_QIDT1*/
			0xe6660000 0x10000 /*CBM_LS*/
			0xe6680000 0x20000 /*CQM ENQ*/
			0xe66C0000 0x40000 /*CQM DEQ*/
			0xe6700000 0x100000 /*FSQM*/
			0xe6800000 0x100000 /*FSQM DESC*/
			0xe6b00000 0x1000 /*TX PUSH*/
			0xe6c00000 0x100000 /*CQM_DMA_DESC_PORT*/
			>;
			interrupt-parent = <&soc_msi>;
			interrupts = <54>, <55>, <56>, <57>,
			<58>, <59>, <60>, <61>;
			interrupt-names = "cqm0", "cqm1","cqm2", "cqm3",
			"cqm4", "cqm5", "cqm6", "cqm7";

			/* clocks */
			clocks = <&cgu0 LGM_CLK_CQEM>, <&cgu0 LGM_GCLK_CQEM>;
			clock-names = "freq", "cbm";
			resets = <&rcu0 0x70 11>;
			reset-names = "cqm";
			power-domains = <&pd_cqm>;
			mxl,syscon = <&sysconf>;
			mxl,bm-buff-size = <&buffer_pool_size>;
			mxl,lpid_config = <&lpid_config>;
			mxl,c55_ddr_mem = <&voice_c55_ddr>;
			mxl,sram-pool = <&cqm_sram>;
			cpupool = <&cpu_pool>;
			syspool = <&sys_pool>;
			rwpool = <&rw_pool>;
			dmas =
				<&dma1tx 0>, <&dma1tx 1>, <&dma1tx 2>, <&dma1tx 3>, <&dma1tx 4>,
				<&dma1tx 5>, <&dma1tx 6>, <&dma1tx 7>, <&dma1tx 8>, <&dma1tx 9>,
				<&dma1tx 10>, <&dma1tx 11>, <&dma1tx 12>, <&dma1tx 13>, <&dma1tx 14>,
				<&dma1tx 15>, <&dma1rx 0>, <&dma1rx 1>, <&dma1rx 2>, <&dma1rx 3>,
				<&dma1rx 4>, <&dma1rx 5>, <&dma1rx 6>, <&dma1rx 7>, <&dma1rx 8>,
				<&dma1rx 9>, <&dma2tx 0>, <&dma2tx 1>, <&dma2tx 2>, <&dma2tx 3>,
				<&dma2tx 4>, <&dma2tx 5>, <&dma2tx 6>, <&dma2tx 7>, <&dma2tx 8>,
				<&dma2tx 9>, <&dma2tx 10>, <&dma2tx 11>, <&dma2tx 12>, <&dma2tx 13>,
				<&dma2tx 14>, <&dma2tx 15>, <&dma0tx 0>, <&dma0tx 1>, <&dma0tx 2>,
				<&dma0tx 3>, <&dma0tx 4>, <&dma0tx 5>, <&dma0tx 6>, <&dma0tx 7>,
				<&dma0tx 8>, <&dma0tx 9>, <&dma0tx 10>, <&dma0tx 11>, <&dma0tx 12>,
				<&dma0tx 13>, <&dma0tx 14>, <&dma0tx 15>;
			dma-names =
				"DMA1TXC0", "DMA1TXC1", "DMA1TXC2", "DMA1TXC3", "DMA1TXC4",
				"DMA1TXC5", "DMA1TXC6", "DMA1TXC7", "DMA1TXC8", "DMA1TXC9",
				"DMA1TXC10", "DMA1TXC11", "DMA1TXC12", "DMA1TXC13", "DMA1TXC14",
				"DMA1TXC15", "DMA1RXC0", "DMA1RXC1", "DMA1RXC2", "DMA1RXC3",
				"DMA1RXC4", "DMA1RXC5", "DMA1RXC6", "DMA1RXC7", "DMA1RXC8",
				"DMA1RXC9", "DMA2TXC0", "DMA2TXC1", "DMA2TXC2", "DMA2TXC3",
				"DMA2TXC4", "DMA2TXC5", "DMA2TXC6", "DMA2TXC7", "DMA2TXC8",
				"DMA2TXC9", "DMA2TXC10", "DMA2TXC11", "DMA2TXC12", "DMA2TXC13",
				"DMA2TXC14", "DMA2TXC15", "DMA0TXC0", "DMA0TXC1", "DMA0TXC2",
				"DMA0TXC3", "DMA0TXC4", "DMA0TXC5", "DMA0TXC6", "DMA0TXC7",
				"DMA0TXC8", "DMA0TXC9", "DMA0TXC10", "DMA0TXC11", "DMA0TXC12",
				"DMA0TXC13","DMA0TXC14","DMA0TXC15";
			mxl,wav-port-resv = <&wav_port_resv>;
			cqm,bm_pools {
				#size-cells = <0>;
				#address-cells = <1>;
				pool@0 {
					reg = <0>;
					pool,buff_sz = <256>;
					/* Default, PON Systems */
					pool,pool-num_buffs = <128 128>;
					pool,type = <SSB_NIOC_SHARED>;
				};
				pool@1 {
					reg = <1>;
					pool,buff_sz = <512>;
					/* Default, PON Systems */
					pool,pool-num_buffs = <9984 130752>;
					pool,type = <CQM_NIOC_SHARED>;
				};
				pool@2 {
					reg = <2>;
					pool,buff_sz = <1024>;
					pool,pool-num_buffs = <3008 34880>;
					pool,type = <CQM_NIOC_SHARED>;
				};
				pool@3 {
				reg = <3>;
					pool,buff_sz = <2048>;
					pool,pool-num_buffs = <215936 290368>;
					pool,type = <CQM_NIOC_SHARED>;
				};
				pool@4 {
					reg = <4>;
					pool,buff_sz = <10240>;
					pool,pool-num_buffs = <2432 6144>;
					pool,type = <CQM_NIOC_SHARED>;
				};
				/* Voice Pool: type = CQM_NIOC_ISOLATED */
				pool@5 {
					reg = <5>;
					pool,buff_sz = <2048>;
					pool,pool-num_buffs = <1024>;
					pool,type = <CQM_NIOC_ISOLATED>;
				};
				/* CPU Pools: type = CQM_CPU_ISOLATED */
				pool@6 {
					reg = <6>;
					pool,buff_sz = <512>;
					pool,pool-num_buffs = <128>;
					pool,type = <CQM_CPU_ISOLATED>;
				};
				pool@7 {
					reg = <7>;
					pool,buff_sz = <1024>;
					pool,pool-num_buffs = <18496>;
					pool,type = <CQM_CPU_ISOLATED>;
				};
				pool@8 {
					reg = <8>;
					pool,buff_sz = <2048>;
					pool,pool-num_buffs = <11328>;
					pool,type = <CQM_CPU_ISOLATED>;
				};
				pool@9 {
					reg = <9>;
					pool,buff_sz = <10240>;
					pool,pool-num_buffs = <512>;
					pool,type = <CQM_CPU_ISOLATED>;
				};
			};
			cqm,bm_policies{
				#size-cells = <0>;
				#address-cells = <1>;
				bm_policy@0 {
					reg=<0>;/* Policy Id */
					policy,pool = <0 DP_RES_ID_SYS>,
						      <1 DP_RES_ID_SYS>; /* Pool Id, Type */
					/* <Min Guaranteed, Max Allowed> */
					policy,alloc = <64 9548 64 130316>; /* If PON is enabled */
					policy,direction = <CQM_TX_RX>;
				};
				bm_policy@1 {
					reg=<1>;
					policy,pool = <1 DP_RES_ID_SYS>;
					policy,alloc = <64 9420 64 130188>;
					policy,direction = <CQM_TX_RX>;
				};
				bm_policy@2 {
					reg=<2>;
					policy,pool = <2 DP_RES_ID_SYS>;
					policy,alloc = <2840 2848 34664 34751>;
					policy,direction = <CQM_TX_RX>;
				};
				bm_policy@3 {
					reg=<3>;
					policy,pool = <3 DP_RES_ID_SYS>;
					policy,alloc = <6296 7870 76839 91976>;
					policy,direction = <CQM_TX_RX>;
				};
				bm_policy@4 {
					reg=<4>;
					policy,pool = <4 DP_RES_ID_SYS>;
					policy,alloc = <2331 2343 6044 6075>;
					policy,direction = <CQM_TX_RX>;
				};
				/* TOE TX policy */
				bm_policy@5 {
					reg=<5>;
					policy,pool = <3 DP_RES_ID_SYS>;
					policy,alloc = <2048 2560>;
					policy,direction = <CQM_TX>;
				};
				/* Radio 1: WAV 2.4G Policies */
				bm_policy@6 {
					reg=<6>;
					policy,pool = <3 DP_RES_ID_WAV614>;
					policy,alloc = <5000 6250>;
					policy,direction = <CQM_RX>;
				};
				bm_policy@7 {
					reg=<7>;
					policy,pool = <3 DP_RES_ID_WAV614>;
					policy,alloc = <10000 12500>;
					policy,direction = <CQM_TX>;
				};
				/* Radio 2: WAV 5/6G Policies */
				bm_policy@8 {
					reg=<8>;
					policy,pool = <3 DP_RES_ID_WAV624>;
					policy,alloc = <10000 12500>;
					policy,direction = <CQM_RX>;
				};
				bm_policy@9 {
					reg=<9>;
					policy,pool = <3 DP_RES_ID_WAV624>;
					policy,alloc = <20000 25000>;
					policy,direction = <CQM_TX>;
				};
				/* Radio 3: WAV 5/6G Policies */
				bm_policy@10 {
					reg=<10>;
					policy,pool = <3 DP_RES_ID_WAV624>;
					policy,alloc = <10000 12500>;
					policy,direction = <CQM_RX>;
				};
				bm_policy@11 {
					reg=<11>;
					policy,pool = <3 DP_RES_ID_WAV624>;
					policy,alloc = <20000 25000>;
					policy,direction = <CQM_TX>;
				};
				/* DSL Policies */
				bm_policy@12 {
					reg=<12>;
					policy,pool = <3 DP_RES_ID_VRX>;
					policy,alloc = <1000 1250 1000 1250>;
					policy,direction = <CQM_RX>;
				};
				bm_policy@13 {
					reg=<13>;
					policy,pool = <1 DP_RES_ID_VRX>;
					policy,alloc = <500 618 500 625>;
					policy,direction = <CQM_TX>;
				};
				bm_policy@14 {
					reg=<14>;
					policy,pool = <2 DP_RES_ID_VRX>;
					policy,alloc = <150 157 150 188>;
					policy,direction = <CQM_TX>;
				};
				bm_policy@15 {
					reg=<15>;
					policy,pool = <3 DP_RES_ID_VRX>;
					policy,alloc = <320 400 320 400>;
					policy,direction = <CQM_TX>;
				};
				bm_policy@16 {
					reg=<16>;
					policy,pool = <4 DP_RES_ID_VRX>;
					policy,alloc = <64 76 64 95>;
					policy,direction = <CQM_TX>;
				};
				/* Voice Policy */
				bm_policy@17 {
					reg=<17>;
					policy,pool = <5 DP_RES_ID_VOICE0>;
					policy,alloc = <1024 1024>;
					policy,direction = <CQM_RX>;
				};
				/* CPU Policies */
				bm_policy@18 {
					reg=<18>;
					policy,pool = <6 DP_RES_ID_CPU> ;
					policy,alloc = <128 128>;
					policy,direction = <CQM_TX_RX>;
				};
				bm_policy@19 {
					reg=<19>;
					policy,pool = <7 DP_RES_ID_CPU>;
					policy,alloc = <18496 18496>;
					policy,direction = <CQM_TX_RX>;
				};
				bm_policy@20 {
					reg=<20>;
					policy,pool = <8 DP_RES_ID_CPU>;
					policy,alloc = <11328 11328>;
					policy,direction = <CQM_TX_RX>;
				};
				bm_policy@21 {
					reg=<21>;
					policy,pool = <9 DP_RES_ID_CPU>;
					policy,alloc = <512 512>;
					policy,direction = <CQM_TX_RX>;
				};
				bm_policy@22 {
					reg=<22>;
					policy,pool = <3 DP_RES_ID_WAV700>;
					policy,alloc = <40000 50000>;
					policy,direction = <CQM_RX>;
				};
				bm_policy@23 {
					reg=<23>;
					policy,pool = <3 DP_RES_ID_WAV700>;
					policy,alloc = <80000 91257 80000 95136>;
					policy,direction = <CQM_TX>;
				};
				bm_policy@24 {
					reg=<24>;
					policy,pool = <1 DP_RES_ID_DOCSIS>;
					policy,alloc = <0 0 48623 50709>;
					policy,direction = <CQM_TX_RX>;
				};
				bm_policy@25 {
					reg=<25>;
					policy,pool = <2 DP_RES_ID_DOCSIS>;
					policy,alloc = <0 0 14587 14721>;
					policy,direction = <CQM_TX_RX>;
				};
				bm_policy@26 {
					reg=<26>;
					policy,pool = <3 DP_RES_ID_DOCSIS>;
					policy,alloc = <0 0 30000 30000>;
					policy,direction = <CQM_TX_RX>;
				};
				bm_policy@27 {
					reg=<27>;
					policy,pool = <4 DP_RES_ID_DOCSIS>;
					policy,alloc = <0 0 1727 1788>;
					policy,direction = <CQM_TX_RX>;
				};
				bm_policy@28 {
					reg=<28>;
					policy,pool = <3 DP_RES_ID_DOCSIS_MMM>;
					policy,alloc = <0 0 128 512>;
					policy,direction = <CQM_TX_RX>;
				};
				bm_policy@29 {
					reg=<29>;
					policy,pool = <3 DP_RES_ID_DOCSIS_VOICE>;
					policy,alloc = <0 0 512 512>;
					policy,direction = <CQM_TX_RX>;
				};
				bm_policy@30 {
					reg=<30>;
					policy,pool = <2 DP_RES_ID_DOCSIS_MPEG>;
					policy,alloc = <0 0 512 512>;
					policy,direction = <CQM_TX_RX>;
				};
			};
		};

		wav_port_resv: wav_port_resv {
			mxl,wav-port-resv=<3 4>;
		};

		wan_xpcs: xpcs@4 {
			compatible = "mxl,lgm-xpcs";
			status = "disabled";
			reg = <0xE7842000 0x400>;
			interrupt-parent = <&ioapic1>;
			interrupts = <59 1>;
			xpcs-name = "wan_xpcs";
			xpcs-mode = <6>; /* <0> - SGMII, <1> - 1000BaseX, <2> - 2500BaseX, <3> - 5GBaseR, <4> - 10GBaseR, <5> - USXGMII, <6> - 10GKR, <7> - QUSXGMII */
			xpcs-cl37 = <3 3 3 0 0 1 0 1>; /* <0> - disable, <1> - SGMII MAC side, <2> - SGMII PHY side, <3> - BaseX */
			xpcs-cl73 = <0 0 0 0 0 0 0 0>; /* <0> - disable, <1> - enable */
			phys = <&wan_xpcs_phy>;
			phy-names = "phy";
			wan_wa = <1>;
		};

		hsiol_xpcs1: xpcs@1 {
			compatible = "mxl,lgm-xpcs";
			status = "disabled";
			reg = <0xD0B42000 0x400>;
			clocks = <&cgu0 LGM_GCLK_XPCS1>;
			interrupt-parent = <&ioapic1>;
			interrupts = <56 1>;
			lineclk,syscon = <&hsiol>;	/* hsiol cbphy1 */
			lineclk,offset = <0x134>;
			lineclk,bit = <0>;
			xpcs-name = "hsiol_xpcs1";
			xpcs-mode = <6>; /* <0> - SGMII, <1> - 1000BaseX, <2> - 2500BaseX, <3> - 5GBaseR, <4> - 10GBaseR, <5> - USXGMII, <6> - 10GKR, <7> - QUSXGMII */
			xpcs-cl37 = <3 3 3 0 0 1 0 1>; /* <0> - disable, <1> - SGMII MAC side, <2> - SGMII PHY side, <3> - BaseX */
			xpcs-cl73 = <0 0 0 0 0 0 0 0>; /* <0> - disable, <1> - enable */
			mpllb = <1>;	/* use MPLL B in 1G mode for HSIO-L/R, use MPLL A in all other modes */
			phys = <&cb0phy1 PHY_TYPE_XPCS_SL>;
			phy-names = "phy";
			slave = <1>;
		};

		hsiol_xpcs0: xpcs@0 {
			compatible = "mxl,lgm-xpcs";
			status = "disabled";
			reg = <	0xD0A42000 0x400>;
			clocks = <&cgu0 LGM_GCLK_XPCS0>;
			interrupt-parent = <&ioapic1>;
			interrupts = <55 1>;
			lineclk,syscon = <&hsiol>;	/* hsiol cbphy0 */
			lineclk,offset = <0x130>;
			lineclk,bit = <0>;
			/*resets = <&rcu0 0x50 12>;*/
			/*resets = <
				&rcu0 0x50 13
				&rcu0 0x50 12
			>;*/
			xpcs-name = "hsiol_xpcs0";
			xpcs-mode = <6>; /* <0> - SGMII, <1> - 1000BaseX, <2> - 2500BaseX, <3> - 5GBaseR, <4> - 10GBaseR, <5> - USXGMII, <6> - 10GKR, <7> - QUSXGMII */
			xpcs-cl37 = <3 3 3 0 0 1 0 1>; /* <0> - disable, <1> - SGMII MAC side, <2> - SGMII PHY side, <3> - BaseX */
			xpcs-cl73 = <0 0 0 0 0 0 0 0>; /* <0> - disable, <1> - enable */
			mpllb = <1>;	/* use MPLL B in 1G mode for HSIO-L/R, use MPLL A in all other modes */
			phys = <&cb0phy0 PHY_TYPE_XPCS_SL>;
			phy-names = "phy";
			pair = <&hsiol_xpcs1>;
		};

		hsior_xpcs1: xpcs@3 {
			compatible = "mxl,lgm-xpcs";
			status = "disabled";
			reg = <	0xC0B42000 0x400>;
			clocks = <&cgu0 LGM_GCLK_XPCS3>;
			interrupt-parent = <&ioapic1>;
			interrupts = <58 1>;
			lineclk,syscon = <&hsior>;	/* hsior cbphy1 */
			lineclk,offset = <0x134>;
			lineclk,bit = <0>;
			xpcs-name = "hsior_xpcs1";
			xpcs-mode = <6>; /* <0> - SGMII, <1> - 1000BaseX, <2> - 2500BaseX, <3> - 5GBaseR, <4> - 10GBaseR, <5> - USXGMII, <6> - 10GKR, <7> - QUSXGMII */
			xpcs-cl37 = <3 3 3 0 0 1 0 1>; /* <0> - disable, <1> - SGMII MAC side, <2> - SGMII PHY side, <3> - BaseX */
			xpcs-cl73 = <0 0 0 0 0 0 0 0>; /* <0> - disable, <1> - enable */
			mpllb = <1>;	/* use MPLL B in 1G mode for HSIO-L/R, use MPLL A in all other modes */
			phys = <&cb2phy1 PHY_TYPE_XPCS_SL>;
			phy-names = "phy";
			slave = <1>;
		};

		hsior_xpcs0: xpcs@2 {
			compatible = "mxl,lgm-xpcs";
			status = "disabled";
			reg = <	0xC0A42000 0x400>;
			clocks = <&cgu0 LGM_GCLK_XPCS2>;
			interrupt-parent = <&ioapic1>;
			interrupts = <57 1>;
			lineclk,syscon = <&hsior>;	/* hsiol cbphy0 */
			lineclk,offset = <0x130>;
			lineclk,bit = <0>;
			/*resets = <&rcu0 0x60 12>;*/
			/* resets = <
				&rcu0 0x60 13
				&rcu0 0x60 12
			>;*/
			xpcs-name = "hsior_xpcs0";
			xpcs-mode = <6>; /* <0> - SGMII, <1> - 1000BaseX, <2> - 2500BaseX, <3> - 5GBaseR, <4> - 10GBaseR, <5> - USXGMII, <6> - 10GKR, <7> - QUSXGMII */
			xpcs-cl37 = <3 3 3 0 0 1 0 1>; /* <0> - disable, <1> - SGMII MAC side, <2> - SGMII PHY side, <3> - BaseX */
			xpcs-cl73 = <0 0 0 0 0 0 0 0>; /* <0> - disable, <1> - enable */
			mpllb = <1>;	/* use MPLL B in 1G mode for HSIO-L/R, use MPLL A in all other modes */
			phys = <&cb2phy0 PHY_TYPE_XPCS_SL>;
			phy-names = "phy";
			pair = <&hsior_xpcs1>;
		};

		gsw: gswitch@E7100000 {
			#address-cells = <1>;
			#size-cells = <1>;
			compatible = "intel,gswdev";
			reg =	<0xE7100000 0x100000>;
			intel,gsw-devid = <0>;
			resets = <&rcu0 0x70 8>;
			reset-names = "gswip";
			clocks = <&cgu0 LGM_CLK_SW>, <&cgu0 LGM_GCLK_GSWIPO>;
			clock-names = "freq", "gate";
			power-domains = <&pd_gsw>;
			intel,aux0-trigger = <INTEL_GSWSS_AUX_TRIG_PONPPS>;
			intel,aux1-trigger = <INTEL_GSWSS_AUX_TRIG_PONPPS>;
			intel,ref-time = <INTEL_GSWSS_REFTIME_XGMAC2>;
			ranges;

			gsw_mac0:gsw_mac@0 {
				compatible = "intel,gsw_mac";
				num_resources = <2>;
				reg =<	0xE7140000 0x2000 /* ADAPTION */
						0xE7142000 0x3000 /* LMAC */
				>;
				interrupt-parent = <&ioapic1>;
				interrupts = <66 1>;
				speed = <10000>;
				clocks = <&cgu0 LGM_CLK_PTP>;
				clock-names = "ptp_clk";
				ext-ref-time = <0>;
				ts-ig-corr = <(-190)>;
				ts-eg-corr = <11>;
				mac_idx = <2>;
				macsec_ig = <&eip160_ig>;
				macsec_eg = <&eip160_eg>;
				xpcs = <&wan_xpcs>;
				pinctrl-names = "default";
				pinctrl-0 = <&pinctrl_mdio_mdc_lan &pinctrl_mdio_mdo_lan>;
				/*board_type = "haps";*/
				mac0_mdio: mdio {
					#address-cells = <1>;
					#size-cells = <0>;
					mdc-clkdiv = <18>;
					gphy0: ethernet-phy@0 {
						reg = <0x0>;
						/* Gphy is not up yet at initial probe.
						 * We set the phy-id here to avoid early
						 * mdio-scan at that point.
						 */
						compatible = "ethernet-phy-id67c9.dc00";
						interrupt-parent = <&ioapic1>;
						/*interrupts = <GIC_SHARED 126 IRQ_TYPE_LEVEL_HIGH>;*/
						mxl,usxgmii-reach = <3>; /* 0(short), 1(medium), 2(long), 3(custom) */
						status = "disabled";
					};
					gphy1: ethernet-phy@1 {
						reg = <0x1>;
						/* Gphy is not up yet at initial probe.
						 * We set the phy-id here to avoid early
						 * mdio-scan at that point.
						 */
						compatible = "ethernet-phy-id67c9.dc00";
						interrupt-parent = <&ioapic1>;
						/*interrupts = <GIC_SHARED 126 IRQ_TYPE_LEVEL_HIGH>;*/
						mxl,usxgmii-reach = <3>; /* 0(short), 1(medium), 2(long), 3(custom) */
						status = "disabled";
					};
					gphy2: ethernet-phy@2 {
						reg = <0x2>;
						/* Gphy is not up yet at initial probe.
						 * We set the phy-id here to avoid early
						 * mdio-scan at that point.
						 */
						compatible = "ethernet-phy-id67c9.dc00";
						interrupt-parent = <&ioapic1>;
						/*interrupts = <GIC_SHARED 126 IRQ_TYPE_LEVEL_HIGH>;*/
						mxl,usxgmii-reach = <3>; /* 0(short), 1(medium), 2(long), 3(custom) */
						status = "disabled";
					};
					gphy3: ethernet-phy@3 {
						reg = <0x3>;
						/* Gphy is not up yet at initial probe.
						 * We set the phy-id here to avoid early
						 * mdio-scan at that point.
						 */
						compatible = "ethernet-phy-id67c9.dc00";
						interrupt-parent = <&ioapic1>;
						/*interrupts = <GIC_SHARED 126 IRQ_TYPE_LEVEL_HIGH>;*/
						mxl,usxgmii-reach = <3>; /* 0(short), 1(medium), 2(long), 3(custom) */
						status = "disabled";
					};
				};
			};

			gsw_mac1:gsw_mac@1 {
				compatible = "intel,gsw_mac";
				num_resources = <2>;
				reg =<	0xE7140000 0x2000 /* ADAPTION */
					0xE7142000 0x3000 /* LMAC */
					>;
				interrupt-parent = <&ioapic1>;
				interrupts = <66 1>;
				speed = <10000>;
				clocks = <&cgu0 LGM_CLK_PTP>;
				clock-names = "ptp_clk";
				ext-ref-time = <1>;
				ts-ig-corr = <(-190)>;
				ts-eg-corr = <11>;
				mac_idx = <3>;
				macsec_ig = <&eip160_ig>;
				macsec_eg = <&eip160_eg>;
				xpcs = <&hsiol_xpcs0>;
				/*board_type = "haps";*/
			};

			gsw_mac2:gsw_mac@2 {
				compatible = "intel,gsw_mac";
				num_resources = <2>;
				reg =<	0xE7140000 0x2000 /* ADAPTION */
					0xE7142000 0x3000 /* LMAC */
					>;
				interrupt-parent = <&ioapic1>;
				interrupts = <66 1>;
				speed = <10000>;
				clocks = <&cgu0 LGM_CLK_PTP>;
				clock-names = "ptp_clk";
				ext-ref-time = <1>;
				ts-ig-corr = <(-190)>;
				ts-eg-corr = <11>;
				mac_idx = <4>;
				macsec_ig = <&eip160_ig>;
				macsec_eg = <&eip160_eg>;
				xpcs = <&hsior_xpcs0>;
				/*board_type = "haps";*/
			};

			gsw_mac3:gsw_mac@3 {
				compatible = "intel,gsw_mac";
				num_resources = <2>;
				reg =<	0xE7140000 0x2000 /* ADAPTION */
					0xE7142000 0x3000 /* LMAC */
					>;
				interrupt-parent = <&ioapic1>;
				interrupts = <66 1>;
				speed = <10000>;
				usxgmii;
				clocks = <&cgu0 LGM_CLK_PTP>;
				clock-names = "ptp_clk";
				ext-ref-time = <1>;
				ts-ig-corr = <(-190)>;
				ts-eg-corr = <11>;
				mac_idx = <5>;
				/*board_type = "haps";*/
			};

			gsw_mac4:gsw_mac@4 {
				compatible = "intel,gsw_mac";
				num_resources = <2>;
				reg =<	0xE7140000 0x2000 /* ADAPTION */
					0xE7142000 0x3000 /* LMAC */
					>;
				interrupt-parent = <&ioapic1>;
				interrupts = <66 1>;
				speed = <10000>;
				usxgmii;
				clocks = <&cgu0 LGM_CLK_PTP>;
				clock-names = "ptp_clk";
				ext-ref-time = <1>;
				ts-ig-corr = <(-190)>;
				ts-eg-corr = <11>;
				mac_idx = <6>;
				/*board_type = "haps";*/
			};

			gsw_mac5:gsw_mac@5 {
				compatible = "intel,gsw_mac";
				num_resources = <2>;
				reg =<	0xE7140000 0x2000 /* ADAPTION */
					0xE7142000 0x3000 /* LMAC */
					>;
				interrupt-parent = <&ioapic1>;
				interrupts = <66 1>;
				speed = <10000>;
				usxgmii;
				clocks = <&cgu0 LGM_CLK_PTP>;
				clock-names = "ptp_clk";
				ext-ref-time = <1>;
				ts-ig-corr = <(-190)>;
				ts-eg-corr = <11>;
				mac_idx = <7>;
				/*board_type = "haps";*/
			};

			gsw_mac6:gsw_mac@6 {
				compatible = "intel,gsw_mac";
				num_resources = <2>;
				reg =<	0xE7140000 0x2000 /* ADAPTION */
					0xE7142000 0x3000 /* LMAC */
					>;
				interrupt-parent = <&ioapic1>;
				interrupts = <66 1>;
				speed = <10000>;
				usxgmii;
				clocks = <&cgu0 LGM_CLK_PTP>;
				clock-names = "ptp_clk";
				ext-ref-time = <1>;
				ts-ig-corr = <(-190)>;
				ts-eg-corr = <11>;
				mac_idx = <8>;
				/*board_type = "haps";*/
			};

			gsw_mac7:gsw_mac@7 {
				compatible = "intel,gsw_mac";
				num_resources = <2>;
				reg =<	0xE7140000 0x2000 /* ADAPTION */
					0xE7142000 0x3000 /* LMAC */
					>;
				interrupt-parent = <&ioapic1>;
				interrupts = <66 1>;
				speed = <10000>;
				clocks = <&cgu0 LGM_CLK_PTP>;
				clock-names = "ptp_clk";
				ext-ref-time = <1>;
				ts-ig-corr = <(-190)>;
				ts-eg-corr = <11>;
				mac_idx = <9>;
				/*xpcs = <&hsiol_xpcs1>;*/
				/*board_type = "haps";*/
			};

			gsw_mac8:gsw_mac@8 {
				compatible = "intel,gsw_mac";
				num_resources = <2>;
				reg =<	0xE7140000 0x2000 /* ADAPTION */
					0xE7142000 0x3000 /* LMAC */
					>;
				interrupt-parent = <&ioapic1>;
				interrupts = <66 1>;
				speed = <10000>;
				clocks = <&cgu0 LGM_CLK_PTP>;
				clock-names = "ptp_clk";
				ext-ref-time = <1>;
				ts-ig-corr = <(-190)>;
				ts-eg-corr = <11>;
				mac_idx = <10>;
				/*xpcs = <&hsior_xpcs1>;*/
				/*board_type = "haps";*/
			};

			gsw_core:gsw_core@9 {
				compatible = "intel,gsw_core";
				num_resources = <1>;
				reg = <0xE7150000 0x4000>;
				interrupt-parent = <&ioapic1>;
				interrupts = <101 1>;
				gsw_mode = <0>;
				mxl,lpid_config = <&lpid_config>;
				intel,gsw-devid = <0>;
			};
		};

		p34x: p34x@0 {
			compatible = "intel,p34x";
			mdio = <&mac0_mdio>;
			interrupt-parent = <&gpio3>;
			interrupts = <3 8>;
			clocks = <&cgu0 LGM_CLK_CML>;
			/*
			resets = <
				&rcu0 0x70 17
				&rcu0 0x70 16
				&rcu0 0x70 15
			>;
			*/
			phyaddr = <0>;
			smdio = <0x1F>;
			rateadaptation = <0>;

			#thermal-sensor-cells = <0>;
			#address-cells = <1>;
			#size-cells = <1>;
			ranges;
			/* Move lan_xpcs node to p34x as a sub device so that
			 * lan_xpcs probe is done after P34X fw download. Note
			 * that this requires P34X driver to create sub device.
			 */
			lan_xpcs: xpcs@5 {
				id = <5>;
				compatible = "mxl,lgm-xpcs";
				status = "disabled";
				reg =<0xE7600000 0x400>;
				clocks = <&cgu0 LGM_CLK_SERDES>;
				interrupt-parent = <&ioapic1>;
				interrupts = <60 1>;
				lineclk,syscon = <&sysconf>;	/* chiptop */
				lineclk,offset = <0x120>;
				lineclk,bit = <16>;
				/*phys = <&lan_xpcs_phy>;*/
				resets = <
					&rcu0 0x70 17
					&rcu0 0x70 16
					&rcu0 0x70 15
				>;
				xpcs-name = "lan_xpcs";
				xpcs-mode = <7>; /* <0> - SGMII, <1> - 1000BaseX, <2> - 2500BaseX, <3> - 5GBaseR, <4> - 10GBaseR, <5> - USXGMII, <6> - 10GKR, <7> - QUSXGMII */
				xpcs-cl37 = <1 3 0 0 0 1 0 1>; /* <0> - disable, <1> - SGMII MAC side, <2> - SGMII PHY side, <3> - BaseX */
				xpcs-cl73 = <0 0 0 0 0 0 0 0>; /* <0> - disable, <1> - enable */
			};
		};

		eth:eth@a00000 {
			#address-cells = <1>;
			#size-cells = <0>;
			#cooling-cells = <2>;
			compatible = "mxl,lgm-eth";
			mxl,eth-cooling-max-state = <4>;
			lantiq,eth-rx-csum-offload = <1>;
			lantiq,eth-switch-mode = <0>;
		};

		vuni: vuni {
			compatible = "mxl,hgu-vuni";
			#address-cells = <1>;
			#size-cells = <0>;
		};

		ponmbox: ponmbox@E7500000 {
			status = "disabled";
			compatible = "intel,urx800-pon-mbox";
			reg =	<0xE7500000 0x80>,
				<0xE7800000 0x10000>,
				<0xE7830000 0x10000>,
				<0xE7840000 0x1000>,
				<0xE7843000 0x1000>;
			reg-names = "ponip", "serdes", "serdes_sram",
				    "pon_app", "pon_apb_app";
			interrupt-parent = <&ioapic1>;
			interrupts = <139 1>, /* PON_IP_RX_INT - level high */
				     <140 1>, /* PON_IP_TX_INT - level high */
				     <171 1>; /* PONIP_IR - level high */
			interrupt-names = "receiver", "transmitter", "general";
			clocks = <&cgu0 LGM_CLK_PONDEF>;
			clock-names = "freq";
			resets = <&rcu0 0x70 9>; /* ponss_rst_n - RST_REQ_ETHNO PON */
			reset-names = "wanss";
			intel,cgu-syscon = <&cgu0>;
			intel,sectop-syscon = <&sec_top>;
			intel,serdes-fw-dl; /* Enable SerDes FW download */
			intel,chiptop-syscon = <&sysconf>; /* Dying gasp support */
			pinctrl-names = "default";
			pinctrl-0 = <&pinctrl_pon_tx>,
				    <&pinctrl_pon_rx_los_0>;
				    /* GPIO9 for internal rogue detection removed
				     * because this pin is not connected to PON-IP.
				     * <&pinctrl_pon_tx_sd>
				     */
		};

		pon_eth: pon_ethernet@2 {
			status = "disabled";
			compatible = "intel,lgm-pon";
			reg = <2>;
			intel,max_ctps = <128>;
			intel,max_gpid = <1>;
		};

		pon_ptp0: pon_ptp@0 {
			compatible = "intel,urx800-pon-ptp";
			reg = <0>;
			status = "disabled";
		};

		pon_ptp1: pon_ptp@1 {
			compatible = "intel,urx800-pon-ptp";
			reg = <1>;
			status = "disabled";
		};

		eip160_ig: eip160@E7400000 {
			compatible = "intel,gsw_macsec";
			status = "okay";
			reg = <0xE7400000 0x10000>;
			reg-names = "e160_reg";
			interrupt-parent = <&ioapic1>;
			interrupts = <109 1>;
			interrupt-names = "e160_irq";
			e160-name = "Ingress";
			e160-devid = <0>;
			gsw = <&gsw>;
		};

		eip160_eg: eip160@E7420000 {
			compatible = "intel,gsw_macsec";
			status = "okay";
			reg = <0xE7420000 0x10000>;
			reg-names = "e160_reg";
			interrupt-parent = <&ioapic1>;
			interrupts = <110 1>;
			interrupt-names = "e160_irq";
			e160-name = "Egress";
			e160-devid = <1>;
			gsw = <&gsw>;
		};

		ppv4: ppv4@f0000000 {
			compatible = "intel,ppv4", "simple-mfd";
			#address-cells = <1>;
			#size-cells = <1>;
			num-sessions = <65536>; /* 64K */
			num-syncqs = <32>;
			frag-mode = <1>; /* (0) - mtu violation checked in uc or (1) - Checked in checker */
			accel-mode = <0>; /* (0) - normal, (1) - unknown L4, (2) - unknown L3 */
			ranges = <0x0 0xf0000000 0x4000000>; /* 64MB */
			power-domains = <&pd_ppv4>;
			clocks = <&cgu0 LGM_CLK_PP_HW>, <&cgu0 LGM_CLK_PP_UC>,
				 <&cgu0 LGM_CLK_PP_FXD>, <&cgu0 LGM_CLK_PP_TBM>;
			clock-names = "ppv4", "uc",
				      "fxd", "tbm";
			rwpool = <&rw_pool>;
			dma_ioc_sz = <0xc8000>; /* 800KB from rw_pool */
			dma_nioc_sz = <0x1E00000>; /* 30MB from rw_pool - depend on num-sessions param */

			infra: infra@0 {
				compatible = "intel,ppv4-infra";
				reg-names = "reg-boot", "reg-clk";
				reg = <0x0 0x14>, <0x1000 0x204>;
			};

			service_log: service_log@3100000 {
			compatible = "intel,ppv4-service-log";
			reg-names = "reg-inga", "reg-ingb", "reg-qos";
			reg = <0x3100000 0x24>, <0x3000880 0x24>, <0x3200400 0x24>;
			};

			parser: parser@100000 {
				compatible = "intel,ppv4-parser";
				reg-names = "reg-config";
				reg = <0x100000 0xE84>;
				parser-profile = <0>;
			};

			rpb: rpb@10000 {
				compatible = "intel,ppv4-rpb";
				reg-names = "reg-drop", "reg-config";
				reg = <0x10000 0x88>, <0x18000 0x934>;
				profile = <0>;
				memory-size = <0x40000>;
				max-pending-packets = <2048>;
			};

			port_dist: port_dist@4000 {
				compatible = "intel,ppv4-port-dist";
				reg-names = "reg-config";
				reg = <0x4000 0x1524>;
			};

			cls: cls@1c00000 {
				compatible = "intel,ppv4-cls";
				reg-names = "reg-config", "reg-cache";
				reg = <0x1C00000 0x808>, <0x1E00C00 0x80>;
				num-lu-threads = <16>;
			};

			chk: chk@1800000 {
				compatible = "intel,ppv4-chk";
				reg-names = "reg-config", "reg-ram",
				    	"reg-cache";
				reg = <0x1800000 0x120>, <0x1900000 0x80004>,
				      <0x1D00000 0x80>;
				num-hw-syncqs = <32>;
				};

			mod: mod@2000000 {
				compatible = "intel,ppv4-mod";
				reg-names = "reg-config", "reg-ram";
				reg = <0x2000000 0x280>, <0x2200000 0x105000>;
			};

			rxdma: rxdma@6000 {
				compatible = "intel,ppv4-rxdma";
				reg-names = "reg-config", "qmgr-push",
					    "qos-query", "wred-response",
					    "bmgr-pop-push";
				reg = <0x6000 0x2800>, <0x30000 0x0>,
				      <0x8000 0x0>, <0x40000 0x0>,
				      <0xC0000 0x0>;
				fsqm-buff-addr = <0xf6c02500>;
				fsqm-desc-addr = <0xf6c02400>;
				fsqm-sram-addr = <0xecd00000>;
				fsqm-sram-sz = <0xa0000>;
				fsqm-max-packet-size = <10240>;
				fsqm-buff-offset = <0x0>;
				buff-size = <&buffer_pool_size>;
			};

			bm: bm@80000 {
				compatible = "intel,ppv4-bm";
				reg-names = "reg-config", "reg-ram", "bmgr-pop-push";
				reg = <0x80000 0xC00>, <0x90000 0x10000>, <0xC0000 0x8000>;
				max-policies = <128>;
				max-groups = <16>;
				max-pools = <16>;
				max-pools-in-policy = <4>;
				pool-pop-hw-en = <1>;
				pcu-fifo-sz = <0x1000>;
			};

			qos: qos@1000000 {
				compatible = "intel,ppv4-qos";
				reg-names = "reg-wred", "reg-uc", "reg-misc-uc",
					    "reg-mbx-to-uc", "reg-bm-base";
				reg = <0x1020000 0x5000>, <0x1040000 0x8100>,
				      <0x1051000 0x80>, <0x1050000 0x1000>, <0xC0000 0x0>;
				max-ports = <256>;
				max-queues = <512>;
				enhanced-wsp = <1>;
				wred-prioritize-pop = <0>;
				wred-total-resources = <196608>;
				wred-p-const = <512>;
				wred-max-q-size = <100000>;
				num-reserved-ports = <256>;
				num-reserved-queues = <64>;
				fw-sec-data-stack-dccm = <1>;
				fw-sec-data-stack-dccm-offset = <0>;
				fw-sec-data-stack-dccm-max-sz = <0x2000>;
			};

			egr_uc: eg_uc@400000 {
				compatible = "intel,ppv4-egr-uc";
				reg-names = "reg-config", "bm-base-addr",
					    "qm-base-addr", "wred-base-addr",
					    "client-base-addr",
					    "txm-cred-base-addr",
					    "chk-base-addr",
					    "chk-cnt-cache-base-addr",
					    "rxdma-base-addr",
					    "cls-base-addr";
				reg = <0x400000 0x400000>, <0xC0000 0x0>,
				      <0x30000 0x0>, <0x8000 0x0>,
				      <0x700000 0x0>, <0x1060000 0x0>,
				      <0x1800000 0x0>, <0x1D00000 0x0>,
				      <0x6000 0x0>, <0x1c00000 0x0>;
				max-cpu = <4>;
				profiles = <1 2 3 4>;
			};

			ing_uc: in_uc@800000 {
				compatible = "intel,ppv4-ing-uc";
				reg-names = "reg-config";
				reg = <0x800000 0x400000>;
				max-cpu = <4>;
				profiles = <0 0 0 1>;
			};
		};

		ssx_voice: ssx_voice@ed200000 {
			status = "disabled";
			#address-cells = <1>;
			#size-cells = <1>;
			compatible = "intel,ssx-voice", "simple-bus";
			reg = <0xed200000 0x200000>;
			ranges = <0x0 0xed200000 0x200000>;
			clock-names = "voice_ct",  "voice_dsp", "voice_4x",
						  "voice_dcl", "voice_c55", "clkout0";
			clocks = <&cgu0 LGM_CLK_CT>,  <&cgu0 LGM_CLK_DSP>,  <&cgu0 LGM_CLK_DSP>,
					 <&cgu0 LGM_CLK_PCM>, <&cgu0 LGM_GCLK_C55>, <&cgu0 LGM_CLK_SLIC>;
			reset-names = "voice_ss";
			resets = <&rcu0 0x10 0x2>;
			intel,syscon = <&sysconf>; /* chiptop */

			cru: cru@d0000 {
				status = "disabled";
				compatible = "intel,lgm-voice-cru";
				reg = <0xd0000 0x100>;
				assigned-clocks = <&cgu0 LGM_CLK_DSP>;
				assigned-clock-rates = <629145600>;
			};

			intc: intc@40000 {
				status = "disabled";
				#interrupt-cells = <1>;
				compatible = "intel,lgm-voice-intc";
				reg = <0x40000 0x20>;
				interrupt-parent = <&ioapic1>;
				interrupts = <50 1>;
				interrupt-controller;
				intel,voice-cru-numbers = <6>;
			};

			irc0: irc0@f6100 {
				status = "disabled";
				#interrupt-cells = <1>;
				compatible = "intel,lgm-voice-irc";
				reg = <0xf6100 0x20>;
				interrupt-parent = <&intc>;
				interrupts = <23>;
				interrupt-controller;
				intel,voice-cru-numbers = <8>;
			};

			irc1: irc1@f7100 {
				status = "disabled";
				#interrupt-cells = <1>;
				compatible = "intel,lgm-voice-irc";
				reg = <0xf7100 0x20>;
				interrupt-parent = <&intc>;
				interrupts = <8>;
				interrupt-controller;
				intel,voice-cru-numbers = <15>;
			};

			c55: c55@c0000 {
				status = "disabled";
				compatible = "intel,lgm-b-c55";
				reg = <0xc0000 0x1e0>, <0x100000 0x40000>, <0x180000 0x10000>;
				interrupt-parent = <&intc>;
				interrupts = <7>;
				intel,voice-mem = <&voice_c55_ddr>;
				/* DSP CRU, DSP PROXY CRU, TDM10 CRU, TDM11 CRU */
				intel,voice-cru-numbers = <0>, <5>, <3>, <4>;
			};

			vcodec0: vcodec@f6000 {
				status = "disabled";
				compatible = "intel,lgm-vcodec";
				reg = <0xf6000 0x100>;
				interrupt-parent = <&irc0>;
				interrupts = <2>;
				reset-names = "vcodec";
				resets = <&rcu0 0x10 3>;
				pinctrl-names = "default";
				pinctrl-0 = <&vcodec_clk &vcodec0_ssi_tx_clk &vcodec0_ssi_rx &vcodec0_ssi_rst>;
				intel,voice-cru-numbers = <7>;

				slic200_0 {
					compatible = "intel,slic200";
					dcdc_type = "IBB";
				};
			};

			vcodec1: vcodec@f7000 {
				status = "disabled";
				compatible = "intel,lgm-vcodec";
				reg = <0xf7000 0x100>;
				interrupt-parent = <&irc1>;
				interrupts = <2>;
				reset-names = "vcodec";
				resets = <&rcu0 0x10 4>;
				pinctrl-names = "default", "ssi_clk";
				pinctrl-0 = <&vcodec1_ssi_tx &vcodec1_ssi_rx &vcodec1_ssi_rst>;
				pinctrl-1 = <&vcodec1_ssi_clk_io19>;
				intel,voice-cru-numbers = <7>;

				slic200_0 {
					compatible = "intel,slic200";
					dcdc_type = "IBB";
				};
			};
		};

		qspi0: qspi@ec000000 {
			status = "disabled";
			compatible = "cadence,qspi";
			reg = <0xec000000 0x100>;
			interrupt-parent = <&ioapic1>;
			interrupts = <36 1>;
			#address-cells = <1>;
			#size-cells = <1>;
			num-chipselect = <2>;
			fifo-depth = <128>;
			ext-decoder = <0>;
			bus-num = <0>;
			lantiq,qspi-port = <0>;
			lantiq,qspi-phyaddr = <0xf4000000>;
			lantiq,qspi-phymask = <0xffffffff>;
			clocks = <&cgu0 LGM_CLK_QSPI>, <&cgu0 LGM_GCLK_QSPI>;
			clock-names = "freq", "qspi";
			resets = <&rcu0 0x10 1>;
			reset-names = "qspi";
			power-domains = <&pd_qspi>;
		};

		noc_pool: noc_pool {
			compatible = "mxl,lgm-gen-pool";

			icc_pool: icc_pool {
				size = <0x4000000>;
				perm = <NOC_RW_PERM>;
			};

			rw_pool: rw_pool {
				size = <0x2100000>;
				perm = <NOC_RW_PERM>;
			};

			cpu_pool: cpu_pool {
				size = <0x2D40000>;
				perm = <NOC_RW_PERM>;
			};

			sys_pool: sys_pool {
				size = <0x1C550000>;
				perm = <NOC_RD_PERM>;
			};

			ro_pool: ro_pool {
				size = <0x600000>;
				perm = <NOC_RD_PERM>;
			};
		};

		noc_fw: noc_fw {
			compatible = "mxl,lgm-noc-firewall";
		};

		noc_fw_default: noc_fw_default {
			compatible = "mxl,lgm-noc-fw-default";
		};

		noc_fw_dl: noc_fw_dl {
			compatible = "mxl,lgm-noc-fw-dl";
			pool = <&ro_pool>;
		};

		umt: umt@e6410000 {
			compatible = "mxl,lgm-umt";
			reg = <0xe6410000 0x10000>;
			clocks = <&cgu0 LGM_CLK_CQEM>;
			clock-names = "freq";
		};

		toe: toe@ecb00000 {
			compatible = "mxl,lgm-toe";
			reg = <
				0xecb00000 0x30e4
				0xecb2d000 0x3000
				0xecb80000 0x18500
				>;
			reg-names = "regs", "ocflags", "lro_dma";
			interrupts-extended = <&soc_msi 0>, <&soc_msi 1>, <&soc_msi 2>,
				<&soc_msi 3>, <&soc_msi 4>, <&soc_msi 5>, <&soc_msi 6>,
				<&soc_msi 7>, <&soc_msi 8>, <&soc_msi 9>, <&soc_msi 10>,
				<&soc_msi 11>, <&soc_msi 12>, <&soc_msi 13>, <&soc_msi 14>,
				<&soc_msi 15>, <&soc_msi 16>, <&soc_msi 17>, <&soc_msi 18>,
				<&soc_msi 19>, <&soc_msi 20>, <&soc_msi 21>, <&soc_msi 22>,
				<&soc_msi 23>, <&soc_msi 24>, <&soc_msi 25>, <&soc_msi 26>,
				<&soc_msi 27>, <&soc_msi 28>, <&soc_msi 29>, <&soc_msi 30>,
				<&soc_msi 31>, <&soc_msi 32>, <&soc_msi 33>, <&soc_msi 34>,
				<&soc_msi 35>, <&ioapic1 81 1>, <&ioapic1 159 1>,
				<&ioapic1 214 1>, <&ioapic1 215 1>;
			interrupt-names = "tso0", "tso1", "tso2", "tso3", "lro0", "lro1",
				"lro2", "lro3", "lro4", "lro5", "lro6", "lro7", "lro8", "lro9",
				"lro10", "lro11", "lro12", "lro13", "lro14", "lro15", "lro16",
				"lro17", "lro18", "lro19", "lro20", "lro21", "lro22", "lro23",
				"lro24", "lro25", "lro26", "lro27", "lro28", "lro29", "lro30",
				"lro31", "tso_int", "lro_sc", "lro_err", "lro_exp";
			clocks = <&cgu0 LGM_GCLK_TOE>;
			clock-names = "g_toe";
			resets = <&rcu0 0x10 8>;
			reset-names = "toe";
			power-domains = <&pd_toe>;
			mxl,sram-pool = <&toe_sram>;
			mxl,ddr-pool = <&rw_pool>;
			dmas =
				/* port 0 */
				<&toe_dma30 4 0 32>, <&toe_dma30 5 0 32>,
				<&toe_dma30 8 0 32>, <&toe_dma30 9 0 32>,
				<&toe_dma30 10 0 32>, <&toe_dma30 11 0 32>,
				<&toe_dma31 4 0 32>, <&toe_dma31 5 0 32>,
				<&toe_dma31 8 0 32>, <&toe_dma31 9 0 32>,
				<&toe_dma31 10 0 32>, <&toe_dma31 11 0 32>,
				/* port 1 */
				<&toe_dma30 6 0 32>, <&toe_dma30 7 0 32>,
				<&toe_dma30 18 0 32>, <&toe_dma30 19 0 32>,
				<&toe_dma30 20 0 32>, <&toe_dma30 21 0 32>,
				<&toe_dma31 6 0 32>, <&toe_dma31 7 0 32>,
				<&toe_dma31 18 0 32>, <&toe_dma31 19 0 32>,
				<&toe_dma31 20 0 32>, <&toe_dma31 21 0 32>,
				/* port 2 */
				<&toe_dma30 14 0 32>, <&toe_dma30 15 0 32>,
				<&toe_dma30 28 0 32>, <&toe_dma30 29 0 32>,
				<&toe_dma30 30 0 32>, <&toe_dma30 31 0 32>,
				<&toe_dma31 14 0 32>, <&toe_dma31 15 0 32>,
				<&toe_dma31 28 0 32>, <&toe_dma31 29 0 32>,
				<&toe_dma31 30 0 32>, <&toe_dma31 31 0 32>,
				/* port 3 */
				<&toe_dma30 16 0 32>, <&toe_dma30 17 0 32>,
				<&toe_dma30 22 0 32>, <&toe_dma30 23 0 32>,
				<&toe_dma30 24 0 32>, <&toe_dma30 25 0 32>,
				<&toe_dma31 16 0 32>, <&toe_dma31 17 0 32>,
				<&toe_dma31 22 0 32>, <&toe_dma31 23 0 32>,
				<&toe_dma31 24 0 32>, <&toe_dma31 25 0 32>;
			dma-names =
				"p0c0", "p0c1", "p0c2", "p0c3", "p0c4", "p0c5",
				"p0c6", "p0c7", "p0c8", "p0c9", "p0c10", "p0c11",
				"p1c0", "p1c1", "p1c2", "p1c3", "p1c4", "p1c5",
				"p1c6", "p1c7", "p1c8", "p1c9", "p1c10", "p1c11",
				"p2c0", "p2c1", "p2c2", "p2c3", "p2c4", "p2c5",
				"p2c6", "p2c7", "p2c8", "p2c9", "p2c10", "p2c11",
				"p3c0", "p3c1", "p3c2", "p3c3", "p3c4", "p3c5",
				"p3c6", "p3c7", "p3c8", "p3c9", "p3c10", "p3c11";
			buff-size = <&buffer_pool_size>;
		};

		sram@e7b00000 {
			compatible = "mmio-sram";
			reg = <0xe7b00000 0x4000>;
			#address-cells = <1>;
			#size-cells = <1>;
			ranges = <0 0xe7b00000 0x4000>;

			vpn_sram: vpn_sram@0 {
				reg = <0x0 0x4000>;
				pool;
			};
		};

		vpn: vpn {
			compatible = "mxl,lgm-vpn-b";
			interrupt-parent = <&ioapic1>;
			interrupts = <95 1>;
			clocks = <&cgu0 LGM_GCLK_ARCEM4>;
			clock-names = "arcem";
			resets = <&rcu0 0x70 12>;
			reset-names = "arcem";
			mxl,sram = <&vpn_sram>;
			mxl,syscon = <&sysconf>; /* chiptop */
			umt-period-us = <14>;
			dma-coherent;
		};
	};

	i2s1:i2s1 { /* i2S1 device node. Currently not supported */
	};
};

#include "lgm_pinctrl.dtsi"

